[part 2 of 2: packages /ComponentType/IvtrIDcLimn/IvtrIDcLimnMAIN to /VehicleProject]
AUTOSAR XML (schema 4.0)
package /ComponentType/IvtrIDcLimn/IvtrIDcLimnMAIN
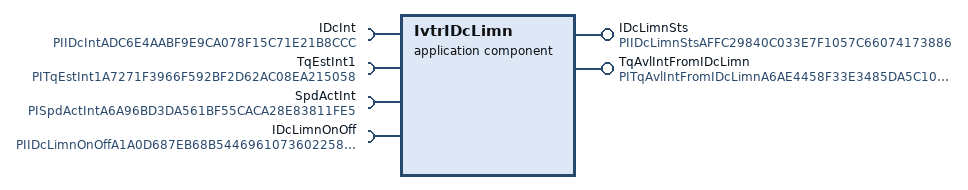
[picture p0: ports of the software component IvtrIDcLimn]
  application sw component type IvtrIDcLimn
    require port IDcInt: nonqueued-receiver-com-spec{data-element=IDcInt, init-value=constant-reference=A566A6590FA167C633F64C4171ADCCB7}, required-interface=PIIDcIntADC6E4AABF9E9CA078F15C71E21B8CCC
    require port TqEstInt1: nonqueued-receiver-com-spec{data-element=TqEstInt1, init-value=constant-reference=A566A6590FA167C633F64C4171ADCCB7}, required-interface=PITqEstInt1A7271F3966F592BF2D62AC08EA215058
    provide port IDcLimnSts: nonqueued-sender-com-spec{data-element=IDcLimnSts, init-value=constant-reference=A2AB2663EDCB674997EFCB4941EAE573}, provided-interface=PIIDcLimnStsAFFC29840C033E7F1057C66074173886
    provide port TqAvlIntFromIDcLimn: nonqueued-sender-com-spec{data-element=TqAvlIntFromIDcLimn, init-value=constant-reference=A6571BE8D08FA8624FE034351C65BBB8}, provided-interface=PITqAvlIntFromIDcLimnA6AE4458F33E3485DA5C10021B0ED5EF
    require port SpdActInt: nonqueued-receiver-com-spec{data-element=SpdActInt, init-value=constant-reference=A566A6590FA167C633F64C4171ADCCB7}, required-interface=PISpdActIntA6A96BD3DA561BF55CACA28E83811FE5
    require port IDcLimnOnOff: nonqueued-receiver-com-spec{data-element=IDcLimnOnOff, init-value=constant-reference=A2AB2663EDCB674997EFCB4941EAE573}, required-interface=PIIDcLimnOnOffA1A0D687EB68B5446961073602258F9F
    behavior BE35d78db7de42c8a51d7b3d700dddb2: handle-termination-and-restart=NO-SUPPORT
      port-api-options:
        enable-take-address=false, indirect-api=false, port=IvtrIDcLimn/IDcInt
        enable-take-address=false, indirect-api=false, port=IvtrIDcLimn/TqEstInt1
        enable-take-address=false, indirect-api=false, port=IDcLimnSts
        enable-take-address=false, indirect-api=false, port=TqAvlIntFromIDcLimn
        enable-take-address=false, indirect-api=false, port=IvtrIDcLimn/SpdActInt
        enable-take-address=false, indirect-api=false, port=IDcLimnOnOff
package /ComponentType/IsgImmo/IsgImmoMAIN
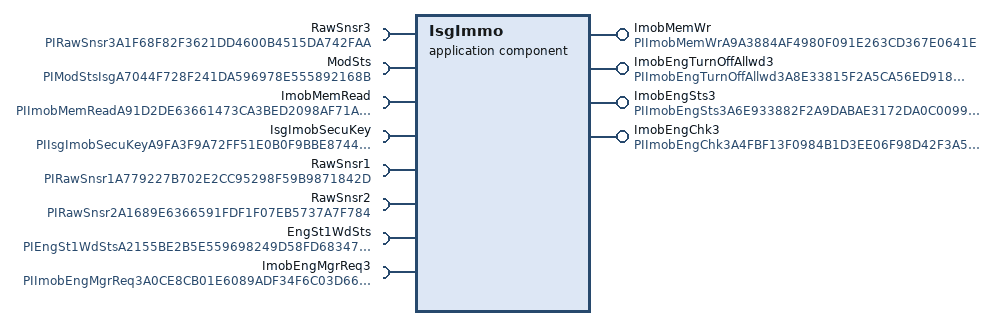
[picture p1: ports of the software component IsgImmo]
  application sw component type IsgImmo
    provide port ImobMemWr: nonqueued-sender-com-spec{data-element=ImobMemWr, init-value=constant-reference=A2AB2663EDCB674997EFCB4941EAE573}, provided-interface=PIImobMemWrA9A3884AF4980F091E263CD367E0641E
    provide port ImobEngTurnOffAllwd3: nonqueued-sender-com-spec{data-element=ImobEngTurnOffAllwd3, init-value=constant-reference=A2AB2663EDCB674997EFCB4941EAE573}, provided-interface=PIImobEngTurnOffAllwd3A8E33815F2A5CA56ED918D0B41C26BA7
    4 x require port:
      RawSnsr3: nonqueued-receiver-com-spec{data-element=RawSnsr3, init-value=constant-reference=A566A6590FA167C633F64C4171ADCCB7}, required-interface=PIRawSnsr3A1F68F82F3621DD4600B4515DA742FAA
      ModSts: nonqueued-receiver-com-spec{data-element=ModStsIsg, init-value=constant-reference=A2AB2663EDCB674997EFCB4941EAE573}, required-interface=PIModStsIsgA7044F728F241DA596978E555892168B
      ImobMemRead: nonqueued-receiver-com-spec{data-element=ImobMemRead, init-value=constant-reference=A2AB2663EDCB674997EFCB4941EAE573}, required-interface=PIImobMemReadA91D2DE63661473CA3BED2098AF71AA2
      IsgImobSecuKey: nonqueued-receiver-com-spec{data-element=IsgImobSecuKey, init-value=constant-reference=AA9EE529BC7CE8EA3A0A158775B5EB0F}, required-interface=PIIsgImobSecuKeyA9FA3F9A72FF51E0B0F9BBE874419BC9
    provide port ImobEngSts3: nonqueued-sender-com-spec{data-element=ImobEngSts3, init-value=constant-reference=A2AB2663EDCB674997EFCB4941EAE573}, provided-interface=PIImobEngSts3A6E933882F2A9DABAE3172DA0C0099F9
    require port RawSnsr1: nonqueued-receiver-com-spec{data-element=RawSnsr1, init-value=constant-reference=A566A6590FA167C633F64C4171ADCCB7}, required-interface=PIRawSnsr1A779227B702E2CC95298F59B9871842D
    require port RawSnsr2: nonqueued-receiver-com-spec{data-element=RawSnsr2, init-value=constant-reference=A566A6590FA167C633F64C4171ADCCB7}, required-interface=PIRawSnsr2A1689E6366591FDF1F07EB5737A7F784
    provide port ImobEngChk3: nonqueued-sender-com-spec{data-element=ImobEngChk3, init-value=constant-reference=A978A77034898F3865BDF257EAEB987B}, provided-interface=PIImobEngChk3A4FBF13F0984B1D3EE06F98D42F3A586
    require port EngSt1WdSts: nonqueued-receiver-com-spec{data-element=EngSt1WdSts, init-value=constant-reference=A636F88E591B4F4A2849AD5E95838F02}, required-interface=PIEngSt1WdStsA2155BE2B5E559698249D58FD6834766
    require port ImobEngMgrReq3: nonqueued-receiver-com-spec{data-element=ImobEngMgrReq3, init-value=constant-reference=A2DE60DBB38156AAEB7CD85B81802804}, required-interface=PIImobEngMgrReq3A0CE8CB01E6089ADF34F6C03D6663521
    behavior BE7ec634f2af4344bb8b143e4ec89d72: handle-termination-and-restart=NO-SUPPORT
      port-api-options:
        enable-take-address=false, indirect-api=false, port=IsgImmo/ImobMemWr
        enable-take-address=false, indirect-api=false, port=ImobEngTurnOffAllwd3
        enable-take-address=false, indirect-api=false, port=IsgImmo/RawSnsr3
        enable-take-address=false, indirect-api=false, port=ModSts
        enable-take-address=false, indirect-api=false, port=IsgImmo/ImobMemRead
        enable-take-address=false, indirect-api=false, port=IsgImmo/IsgImobSecuKey
        enable-take-address=false, indirect-api=false, port=IsgImmo/ImobEngSts3
        enable-take-address=false, indirect-api=false, port=IsgImmo/RawSnsr1
        enable-take-address=false, indirect-api=false, port=IsgImmo/RawSnsr2
        enable-take-address=false, indirect-api=false, port=IsgImmo/ImobEngChk3
        enable-take-address=false, indirect-api=false, port=IsgImmo/EngSt1WdSts
        enable-take-address=false, indirect-api=false, port=IsgImmo/ImobEngMgrReq3
package /ComponentType/CMACIDDIfCptOut/CMACIDDIfCptOutMAIN
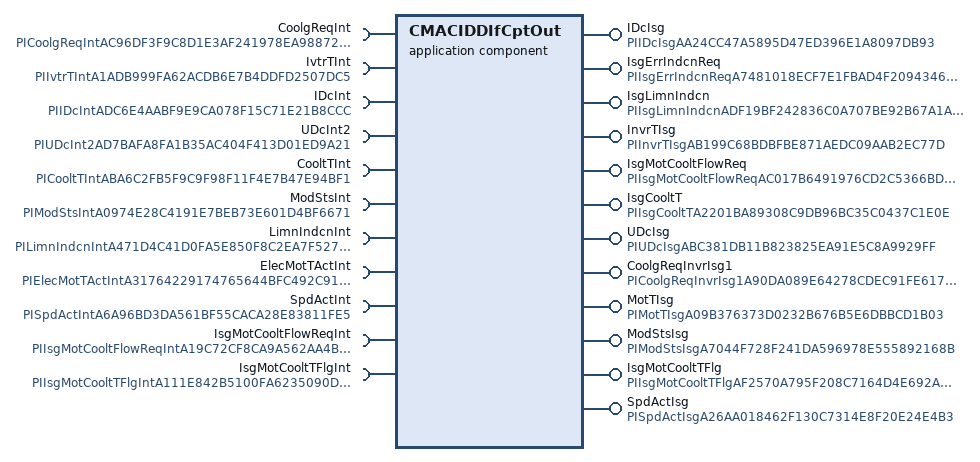
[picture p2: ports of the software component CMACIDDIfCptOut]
  application sw component type CMACIDDIfCptOut
    7 x require port:
      CoolgReqInt: nonqueued-receiver-com-spec{data-element=CoolgReqInt, init-value=constant-reference=A2AB2663EDCB674997EFCB4941EAE573}, required-interface=PICoolgReqIntAC96DF3F9C8D1E3AF241978EA9887249
      IvtrTInt: nonqueued-receiver-com-spec{data-element=IvtrTInt, init-value=constant-reference=A566A6590FA167C633F64C4171ADCCB7}, required-interface=PIIvtrTIntA1ADB999FA62ACDB6E7B4DDFD2507DC5
      IDcInt: nonqueued-receiver-com-spec{data-element=IDcInt, init-value=constant-reference=A566A6590FA167C633F64C4171ADCCB7}, required-interface=PIIDcIntADC6E4AABF9E9CA078F15C71E21B8CCC
      UDcInt2: nonqueued-receiver-com-spec{data-element=UDcInt2, init-value=constant-reference=A566A6590FA167C633F64C4171ADCCB7}, required-interface=PIUDcInt2AD7BAFA8FA1B35AC404F413D01ED9A21
      CooltTInt: nonqueued-receiver-com-spec{data-element=CooltTInt, init-value=constant-reference=A566A6590FA167C633F64C4171ADCCB7}, required-interface=PICooltTIntABA6C2FB5F9C9F98F11F4E7B47E94BF1
      ModStsInt: nonqueued-receiver-com-spec{data-element=ModStsInt, init-value=constant-reference=A2AB2663EDCB674997EFCB4941EAE573}, required-interface=PIModStsIntA0974E28C4191E7BEB73E601D4BF6671
      LimnIndcnInt: nonqueued-receiver-com-spec{data-element=LimnIndcnInt, init-value=constant-reference=A2AB2663EDCB674997EFCB4941EAE573}, required-interface=PILimnIndcnIntA471D4C41D0FA5E850F8C2EA7F52740F
    provide port IDcIsg: nonqueued-sender-com-spec{data-element=IDcIsg, init-value=constant-reference=A566A6590FA167C633F64C4171ADCCB7}, provided-interface=PIIDcIsgAA24CC47A5895D47ED396E1A8097DB93
    provide port IsgErrIndcnReq: nonqueued-sender-com-spec{data-element=IsgErrIndcnReq, init-value=constant-reference=A2AB2663EDCB674997EFCB4941EAE573}, provided-interface=PIIsgErrIndcnReqA7481018ECF7E1FBAD4F2094346D0B08
    require port ElecMotTActInt: nonqueued-receiver-com-spec{data-element=ElecMotTActInt, init-value=constant-reference=A566A6590FA167C633F64C4171ADCCB7}, required-interface=PIElecMotTActIntA31764229174765644BFC492C91799B4
    6 x provide port:
      IsgLimnIndcn: nonqueued-sender-com-spec{data-element=IsgLimnIndcn, init-value=constant-reference=A2AB2663EDCB674997EFCB4941EAE573}, provided-interface=PIIsgLimnIndcnADF19BF242836C0A707BE92B67A1A3C9
      InvrTIsg: nonqueued-sender-com-spec{data-element=InvrTIsg, init-value=constant-reference=A566A6590FA167C633F64C4171ADCCB7}, provided-interface=PIInvrTIsgAB199C68BDBFBE871AEDC09AAB2EC77D
      IsgMotCooltFlowReq: nonqueued-sender-com-spec{data-element=IsgMotCooltFlowReq, init-value=constant-reference=A566A6590FA167C633F64C4171ADCCB7}, provided-interface=PIIsgMotCooltFlowReqAC017B6491976CD2C5366BD7CAC36C21
      IsgCooltT: nonqueued-sender-com-spec{data-element=IsgCooltT, init-value=constant-reference=A566A6590FA167C633F64C4171ADCCB7}, provided-interface=PIIsgCooltTA2201BA89308C9DB96BC35C0437C1E0E
      UDcIsg: nonqueued-sender-com-spec{data-element=UDcIsg, init-value=constant-reference=A566A6590FA167C633F64C4171ADCCB7}, provided-interface=PIUDcIsgABC381DB11B823825EA91E5C8A9929FF
      CoolgReqInvrIsg1: nonqueued-sender-com-spec{data-element=CoolgReqInvrIsg1, init-value=constant-reference=A2AB2663EDCB674997EFCB4941EAE573}, provided-interface=PICoolgReqInvrIsg1A90DA089E64278CDEC91FE617833644E
    require port SpdActInt: nonqueued-receiver-com-spec{data-element=SpdActInt, init-value=constant-reference=A566A6590FA167C633F64C4171ADCCB7}, required-interface=PISpdActIntA6A96BD3DA561BF55CACA28E83811FE5
    provide port MotTIsg: nonqueued-sender-com-spec{data-element=MotTIsg, init-value=constant-reference=A566A6590FA167C633F64C4171ADCCB7}, provided-interface=PIMotTIsgA09B376373D0232B676B5E6DBBCD1B03
    require port IsgMotCooltFlowReqInt: nonqueued-receiver-com-spec{data-element=IsgMotCooltFlowReqInt, init-value=constant-reference=A566A6590FA167C633F64C4171ADCCB7}, required-interface=PIIsgMotCooltFlowReqIntA19C72CF8CA9A562AA4BC89712FF8931
    provide port ModStsIsg: nonqueued-sender-com-spec{data-element=ModStsIsg, init-value=constant-reference=A2AB2663EDCB674997EFCB4941EAE573}, provided-interface=PIModStsIsgA7044F728F241DA596978E555892168B
    provide port IsgMotCooltTFlg: nonqueued-sender-com-spec{data-element=IsgMotCooltTFlg, init-value=constant-reference=A2AB2663EDCB674997EFCB4941EAE573}, provided-interface=PIIsgMotCooltTFlgAF2570A795F208C7164D4E692AD44EF5
    require port IsgMotCooltTFlgInt: nonqueued-receiver-com-spec{data-element=IsgMotCooltTFlgInt, init-value=constant-reference=AD30053758475D867C29EE0F5723584A}, required-interface=PIIsgMotCooltTFlgIntA111E842B5100FA6235090DA6780D515
    provide port SpdActIsg: nonqueued-sender-com-spec{data-element=SpdActIsg, init-value=constant-reference=A2AB2663EDCB674997EFCB4941EAE573}, provided-interface=PISpdActIsgA26AA018462F130C7314E8F20E24E4B3
    behavior BEff149eeec84c2b8b5259282cef4e47: handle-termination-and-restart=NO-SUPPORT
      port-api-options:
        enable-take-address=false, indirect-api=false, port=CoolgReqInt
        enable-take-address=false, indirect-api=false, port=CMACIDDIfCptOut/IvtrTInt
        enable-take-address=false, indirect-api=false, port=CMACIDDIfCptOut/IDcInt
        enable-take-address=false, indirect-api=false, port=CMACIDDIfCptOut/UDcInt2
        enable-take-address=false, indirect-api=false, port=CMACIDDIfCptOut/CooltTInt
        enable-take-address=false, indirect-api=false, port=ModStsInt
        enable-take-address=false, indirect-api=false, port=LimnIndcnInt
        enable-take-address=false, indirect-api=false, port=CMACIDDIfCptOut/IDcIsg
        enable-take-address=false, indirect-api=false, port=CMACIDDIfCptOut/IsgErrIndcnReq
        enable-take-address=false, indirect-api=false, port=CMACIDDIfCptOut/ElecMotTActInt
        enable-take-address=false, indirect-api=false, port=CMACIDDIfCptOut/IsgLimnIndcn
        enable-take-address=false, indirect-api=false, port=CMACIDDIfCptOut/InvrTIsg
        enable-take-address=false, indirect-api=false, port=CMACIDDIfCptOut/IsgMotCooltFlowReq
        enable-take-address=false, indirect-api=false, port=CMACIDDIfCptOut/IsgCooltT
        enable-take-address=false, indirect-api=false, port=CMACIDDIfCptOut/UDcIsg
        enable-take-address=false, indirect-api=false, port=CMACIDDIfCptOut/CoolgReqInvrIsg1
        enable-take-address=false, indirect-api=false, port=CMACIDDIfCptOut/SpdActInt
        enable-take-address=false, indirect-api=false, port=CMACIDDIfCptOut/MotTIsg
        enable-take-address=false, indirect-api=false, port=IsgMotCooltFlowReqInt
        enable-take-address=false, indirect-api=false, port=CMACIDDIfCptOut/ModStsIsg
        enable-take-address=false, indirect-api=false, port=CMACIDDIfCptOut/IsgMotCooltTFlg
        enable-take-address=false, indirect-api=false, port=IsgMotCooltTFlgInt
        enable-take-address=false, indirect-api=false, port=CMACIDDIfCptOut/SpdActIsg
package /ComponentType/IvtrAntiSpin/IvtrAntiSpinMAIN
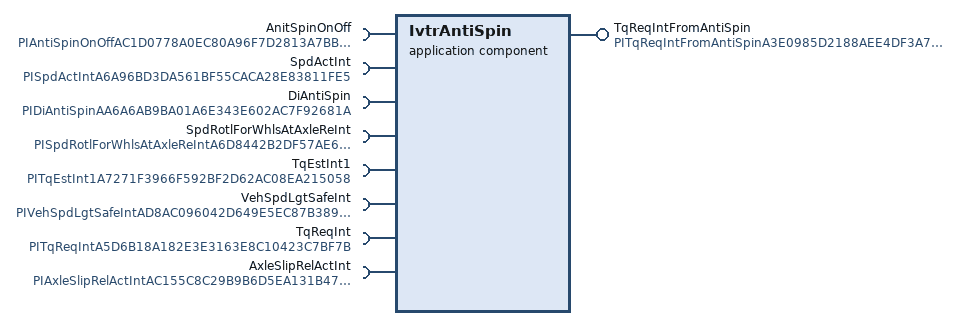
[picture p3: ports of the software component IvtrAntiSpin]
  application sw component type IvtrAntiSpin
    require port AnitSpinOnOff: nonqueued-receiver-com-spec{data-element=AntiSpinOnOff, init-value=constant-reference=AD30053758475D867C29EE0F5723584A}, required-interface=PIAntiSpinOnOffAC1D0778A0EC80A96F7D2813A7BB259C
    require port SpdActInt: nonqueued-receiver-com-spec{data-element=SpdActInt, init-value=constant-reference=A566A6590FA167C633F64C4171ADCCB7}, required-interface=PISpdActIntA6A96BD3DA561BF55CACA28E83811FE5
    provide port TqReqIntFromAntiSpin: nonqueued-sender-com-spec{data-element=TqReqIntFromAntiSpin, init-value=constant-reference=A566A6590FA167C633F64C4171ADCCB7}, provided-interface=PITqReqIntFromAntiSpinA3E0985D2188AEE4DF3A78C4373D692A
    6 x require port:
      DiAntiSpin: nonqueued-receiver-com-spec{data-element=DiAntiSpin, init-value=constant-reference=AD30053758475D867C29EE0F5723584A}, required-interface=PIDiAntiSpinAA6A6AB9BA01A6E343E602AC7F92681A
      SpdRotlForWhlsAtAxleReInt: nonqueued-receiver-com-spec{data-element=SpdRotlForWhlsAtAxleReInt, init-value=constant-reference=A566A6590FA167C633F64C4171ADCCB7}, required-interface=PISpdRotlForWhlsAtAxleReIntA6D8442B2DF57AE61F7FA90FE332F100
      TqEstInt1: nonqueued-receiver-com-spec{data-element=TqEstInt1, init-value=constant-reference=A566A6590FA167C633F64C4171ADCCB7}, required-interface=PITqEstInt1A7271F3966F592BF2D62AC08EA215058
      VehSpdLgtSafeInt: nonqueued-receiver-com-spec{data-element=VehSpdLgtSafeInt, init-value=constant-reference=A68FE985916865C70A611D0FFC6B9CF2}, required-interface=PIVehSpdLgtSafeIntAD8AC096042D649E5EC87B3898F1B812
      TqReqInt: nonqueued-receiver-com-spec{data-element=TqReqInt, init-value=constant-reference=A566A6590FA167C633F64C4171ADCCB7}, required-interface=PITqReqIntA5D6B18A182E3E3163E8C10423C7BF7B
      AxleSlipRelActInt: nonqueued-receiver-com-spec{data-element=AxleSlipRelActInt, init-value=constant-reference=A566A6590FA167C633F64C4171ADCCB7}, required-interface=PIAxleSlipRelActIntAC155C8C29B9B6D5EA131B477AEAA643
    behavior BEb162d0eb2e4f02bc2c140d4cab38fc: handle-termination-and-restart=NO-SUPPORT
      port-api-options:
        enable-take-address=false, indirect-api=false, port=AnitSpinOnOff
        enable-take-address=false, indirect-api=false, port=IvtrAntiSpin/SpdActInt
        enable-take-address=false, indirect-api=false, port=TqReqIntFromAntiSpin
        enable-take-address=false, indirect-api=false, port=DiAntiSpin
        enable-take-address=false, indirect-api=false, port=IvtrAntiSpin/SpdRotlForWhlsAtAxleReInt
        enable-take-address=false, indirect-api=false, port=IvtrAntiSpin/TqEstInt1
        enable-take-address=false, indirect-api=false, port=VehSpdLgtSafeInt
        enable-take-address=false, indirect-api=false, port=IvtrAntiSpin/TqReqInt
        enable-take-address=false, indirect-api=false, port=AxleSlipRelActInt
package /ComponentType/IvtrElecMotTLimn/IvtrElecMotTLimnMAIN
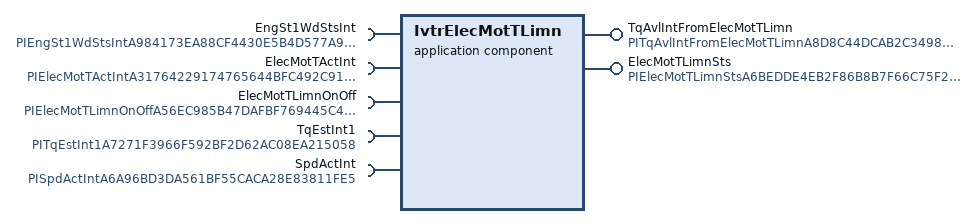
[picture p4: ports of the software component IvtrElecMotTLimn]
  application sw component type IvtrElecMotTLimn
    require port EngSt1WdStsInt: nonqueued-receiver-com-spec{data-element=EngSt1WdStsInt, init-value=constant-reference=A636F88E591B4F4A2849AD5E95838F02}, required-interface=PIEngSt1WdStsIntA984173EA88CF4430E5B4D577A9BEE8A
    require port ElecMotTActInt: nonqueued-receiver-com-spec{data-element=ElecMotTActInt, init-value=constant-reference=A566A6590FA167C633F64C4171ADCCB7}, required-interface=PIElecMotTActIntA31764229174765644BFC492C91799B4
    provide port TqAvlIntFromElecMotTLimn: nonqueued-sender-com-spec{data-element=TqAvlIntFromElecMotTLimn, init-value=constant-reference=A6571BE8D08FA8624FE034351C65BBB8}, provided-interface=PITqAvlIntFromElecMotTLimnA8D8C44DCAB2C3498F4B4354A447D7C6
    require port ElecMotTLimnOnOff: nonqueued-receiver-com-spec{data-element=ElecMotTLimnOnOff, init-value=constant-reference=A2AB2663EDCB674997EFCB4941EAE573}, required-interface=PIElecMotTLimnOnOffA56EC985B47DAFBF769445C481FDAB70
    require port TqEstInt1: nonqueued-receiver-com-spec{data-element=TqEstInt1, init-value=constant-reference=A566A6590FA167C633F64C4171ADCCB7}, required-interface=PITqEstInt1A7271F3966F592BF2D62AC08EA215058
    provide port ElecMotTLimnSts: nonqueued-sender-com-spec{data-element=ElecMotTLimnSts, init-value=constant-reference=A2AB2663EDCB674997EFCB4941EAE573}, provided-interface=PIElecMotTLimnStsA6BEDDE4EB2F86B8B7F66C75F285B97F
    require port SpdActInt: nonqueued-receiver-com-spec{data-element=SpdActInt, init-value=constant-reference=A566A6590FA167C633F64C4171ADCCB7}, required-interface=PISpdActIntA6A96BD3DA561BF55CACA28E83811FE5
    behavior BE808a822f444aabb96fe5b11ea65a39: handle-termination-and-restart=NO-SUPPORT
      port-api-options:
        enable-take-address=false, indirect-api=false, port=IvtrElecMotTLimn/EngSt1WdStsInt
        enable-take-address=false, indirect-api=false, port=IvtrElecMotTLimn/ElecMotTActInt
        enable-take-address=false, indirect-api=false, port=TqAvlIntFromElecMotTLimn
        enable-take-address=false, indirect-api=false, port=ElecMotTLimnOnOff
        enable-take-address=false, indirect-api=false, port=IvtrElecMotTLimn/TqEstInt1
        enable-take-address=false, indirect-api=false, port=ElecMotTLimnSts
        enable-take-address=false, indirect-api=false, port=IvtrElecMotTLimn/SpdActInt
package /ComponentType/IvtrUDcLimn/IvtrUDcLimnMAIN
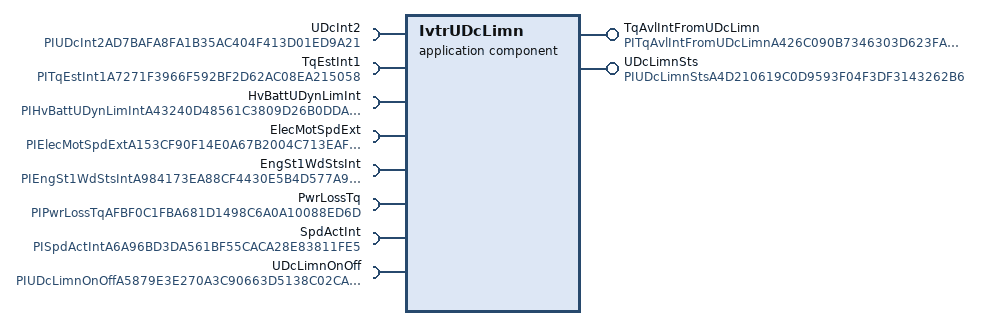
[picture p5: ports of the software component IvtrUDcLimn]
  application sw component type IvtrUDcLimn
    provide port TqAvlIntFromUDcLimn: nonqueued-sender-com-spec{data-element=TqAvlIntFromUDcLimn, init-value=constant-reference=A8CFFE3621C1DA13E6FF691AE3A9D3C1}, provided-interface=PITqAvlIntFromUDcLimnA426C090B7346303D623FAFF22E09D3B
    7 x require port:
      UDcInt2: nonqueued-receiver-com-spec{data-element=UDcInt2, init-value=constant-reference=A566A6590FA167C633F64C4171ADCCB7}, required-interface=PIUDcInt2AD7BAFA8FA1B35AC404F413D01ED9A21
      TqEstInt1: nonqueued-receiver-com-spec{data-element=TqEstInt1, init-value=constant-reference=A566A6590FA167C633F64C4171ADCCB7}, required-interface=PITqEstInt1A7271F3966F592BF2D62AC08EA215058
      HvBattUDynLimInt: nonqueued-receiver-com-spec{data-element=HvBattUDynLimInt, init-value=constant-reference=A475F4F393542C3A8168E5F3043367CB}, required-interface=PIHvBattUDynLimIntA43240D48561C3809D26B0DDADA0994C
      ElecMotSpdExt: nonqueued-receiver-com-spec{data-element=ElecMotSpdExt, init-value=constant-reference=A566A6590FA167C633F64C4171ADCCB7}, required-interface=PIElecMotSpdExtA153CF90F14E0A67B2004C713EAF537C
      EngSt1WdStsInt: nonqueued-receiver-com-spec{data-element=EngSt1WdStsInt, init-value=constant-reference=A636F88E591B4F4A2849AD5E95838F02}, required-interface=PIEngSt1WdStsIntA984173EA88CF4430E5B4D577A9BEE8A
      PwrLossTq: nonqueued-receiver-com-spec{data-element=PwrLossTq, init-value=constant-reference=A566A6590FA167C633F64C4171ADCCB7}, required-interface=PIPwrLossTqAFBF0C1FBA681D1498C6A0A10088ED6D
      SpdActInt: nonqueued-receiver-com-spec{data-element=SpdActInt, init-value=constant-reference=A566A6590FA167C633F64C4171ADCCB7}, required-interface=PISpdActIntA6A96BD3DA561BF55CACA28E83811FE5
    provide port UDcLimnSts: nonqueued-sender-com-spec{data-element=UDcLimnSts, init-value=constant-reference=A2AB2663EDCB674997EFCB4941EAE573}, provided-interface=PIUDcLimnStsA4D210619C0D9593F04F3DF3143262B6
    require port UDcLimnOnOff: nonqueued-receiver-com-spec{data-element=UDcLimnOnOff, init-value=constant-reference=A2AB2663EDCB674997EFCB4941EAE573}, required-interface=PIUDcLimnOnOffA5879E3E270A3C90663D5138C02CA256
    behavior BE011aebbdd8486cb71f85ab897cc588: handle-termination-and-restart=NO-SUPPORT
      port-api-options:
        enable-take-address=false, indirect-api=false, port=TqAvlIntFromUDcLimn
        enable-take-address=false, indirect-api=false, port=IvtrUDcLimn/UDcInt2
        enable-take-address=false, indirect-api=false, port=IvtrUDcLimn/TqEstInt1
        enable-take-address=false, indirect-api=false, port=HvBattUDynLimInt
        enable-take-address=false, indirect-api=false, port=IvtrUDcLimn/ElecMotSpdExt
        enable-take-address=false, indirect-api=false, port=IvtrUDcLimn/EngSt1WdStsInt
        enable-take-address=false, indirect-api=false, port=PwrLossTq
        enable-take-address=false, indirect-api=false, port=IvtrUDcLimn/SpdActInt
        enable-take-address=false, indirect-api=false, port=UDcLimnSts
        enable-take-address=false, indirect-api=false, port=UDcLimnOnOff
package /ComponentType/IvtrSpdSetCtrl/IvtrSpdSetCtrlMAIN
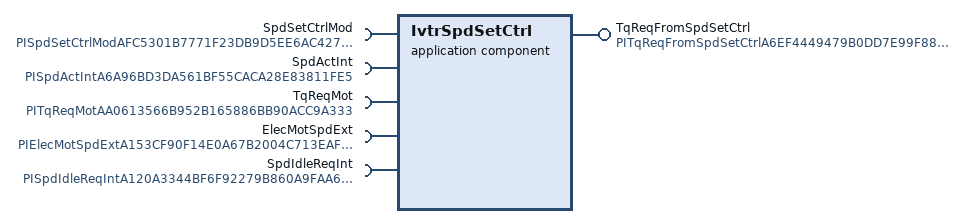
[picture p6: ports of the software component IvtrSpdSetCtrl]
  application sw component type IvtrSpdSetCtrl
    require port SpdSetCtrlMod: nonqueued-receiver-com-spec{data-element=SpdSetCtrlMod, init-value=constant-reference=A2AB2663EDCB674997EFCB4941EAE573}, required-interface=PISpdSetCtrlModAFC5301B7771F23DB9D5EE6AC427D0DF
    provide port TqReqFromSpdSetCtrl: nonqueued-sender-com-spec{data-element=TqReqFromSpdSetCtrl, init-value=constant-reference=A566A6590FA167C633F64C4171ADCCB7}, provided-interface=PITqReqFromSpdSetCtrlA6EF4449479B0DD7E99F884852E50B53
    4 x require port:
      SpdActInt: nonqueued-receiver-com-spec{data-element=SpdActInt, init-value=constant-reference=A566A6590FA167C633F64C4171ADCCB7}, required-interface=PISpdActIntA6A96BD3DA561BF55CACA28E83811FE5
      TqReqMot: nonqueued-receiver-com-spec{data-element=TqReqMot, init-value=constant-reference=A566A6590FA167C633F64C4171ADCCB7}, required-interface=PITqReqMotAA0613566B952B165886BB90ACC9A333
      ElecMotSpdExt: nonqueued-receiver-com-spec{data-element=ElecMotSpdExt, init-value=constant-reference=A566A6590FA167C633F64C4171ADCCB7}, required-interface=PIElecMotSpdExtA153CF90F14E0A67B2004C713EAF537C
      SpdIdleReqInt: nonqueued-receiver-com-spec{data-element=SpdIdleReqInt, init-value=constant-reference=A566A6590FA167C633F64C4171ADCCB7}, required-interface=PISpdIdleReqIntA120A3344BF6F92279B860A9FAA6ECAE
    behavior BEadc5c64acc4f2e90d294c4262b7282: handle-termination-and-restart=NO-SUPPORT
      port-api-options:
        enable-take-address=false, indirect-api=false, port=SpdSetCtrlMod
        enable-take-address=false, indirect-api=false, port=TqReqFromSpdSetCtrl
        enable-take-address=false, indirect-api=false, port=IvtrSpdSetCtrl/SpdActInt
        enable-take-address=false, indirect-api=false, port=IvtrSpdSetCtrl/TqReqMot
        enable-take-address=false, indirect-api=false, port=IvtrSpdSetCtrl/ElecMotSpdExt
        enable-take-address=false, indirect-api=false, port=SpdIdleReqInt
package /ComponentType/IvtrErrIndcn/IvtrErrIndcnMAIN
  application sw component type IvtrErrIndcn
    behavior BE44068fd61445ff8b9ba4e3c95e7bb1: handle-termination-and-restart=NO-SUPPORT
package /ComponentType/IvtrElecMotTqAvlCalcn/IvtrElecMotTqAvlCalcnMAIN
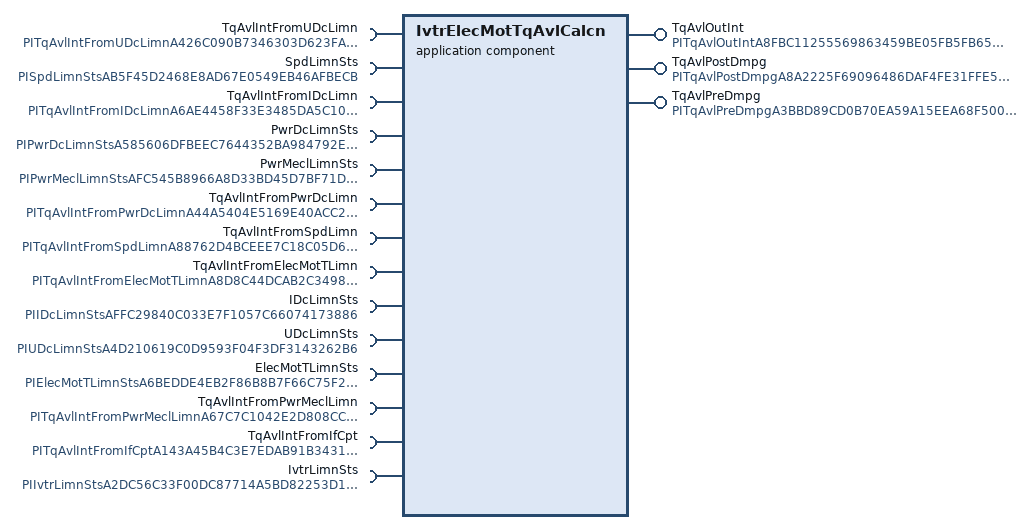
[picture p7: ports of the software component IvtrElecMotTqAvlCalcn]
  application sw component type IvtrElecMotTqAvlCalcn
    require port TqAvlIntFromUDcLimn: nonqueued-receiver-com-spec{data-element=TqAvlIntFromUDcLimn, init-value=constant-reference=A8CFFE3621C1DA13E6FF691AE3A9D3C1}, required-interface=PITqAvlIntFromUDcLimnA426C090B7346303D623FAFF22E09D3B
    require port SpdLimnSts: nonqueued-receiver-com-spec{data-element=SpdLimnSts, init-value=constant-reference=A2AB2663EDCB674997EFCB4941EAE573}, required-interface=PISpdLimnStsAB5F45D2468E8AD67E0549EB46AFBECB
    provide port TqAvlOutInt: nonqueued-sender-com-spec{data-element=TqAvlOutInt, init-value=constant-reference=A8CFFE3621C1DA13E6FF691AE3A9D3C1}, provided-interface=PITqAvlOutIntA8FBC11255569863459BE05FB5FB6599
    6 x require port:
      TqAvlIntFromIDcLimn: nonqueued-receiver-com-spec{data-element=TqAvlIntFromIDcLimn, init-value=constant-reference=A8CFFE3621C1DA13E6FF691AE3A9D3C1}, required-interface=PITqAvlIntFromIDcLimnA6AE4458F33E3485DA5C10021B0ED5EF
      PwrDcLimnSts: nonqueued-receiver-com-spec{data-element=PwrDcLimnSts, init-value=constant-reference=A2AB2663EDCB674997EFCB4941EAE573}, required-interface=PIPwrDcLimnStsA585606DFBEEC7644352BA984792E3DF
      PwrMeclLimnSts: nonqueued-receiver-com-spec{data-element=PwrMeclLimnSts, init-value=constant-reference=A2AB2663EDCB674997EFCB4941EAE573}, required-interface=PIPwrMeclLimnStsAFC545B8966A8D33BD45D7BF71D6D720
      TqAvlIntFromPwrDcLimn: nonqueued-receiver-com-spec{data-element=TqAvlIntFromPwrDcLimn, init-value=constant-reference=A8CFFE3621C1DA13E6FF691AE3A9D3C1}, required-interface=PITqAvlIntFromPwrDcLimnA44A5404E5169E40ACC2FA97F3F218EE
      TqAvlIntFromSpdLimn: nonqueued-receiver-com-spec{data-element=TqAvlIntFromSpdLimn, init-value=constant-reference=A8CFFE3621C1DA13E6FF691AE3A9D3C1}, required-interface=PITqAvlIntFromSpdLimnA88762D4BCEEE7C18C05D620D2A53FB7
      TqAvlIntFromElecMotTLimn: nonqueued-receiver-com-spec{data-element=TqAvlIntFromElecMotTLimn, init-value=constant-reference=A8CFFE3621C1DA13E6FF691AE3A9D3C1}, required-interface=PITqAvlIntFromElecMotTLimnA8D8C44DCAB2C3498F4B4354A447D7C6
    provide port TqAvlPostDmpg: nonqueued-sender-com-spec{data-element=TqAvlPostDmpg, init-value=constant-reference=A8CFFE3621C1DA13E6FF691AE3A9D3C1}, provided-interface=PITqAvlPostDmpgA8A2225F69096486DAF4FE31FFE52A89
    provide port TqAvlPreDmpg: nonqueued-sender-com-spec{data-element=TqAvlPreDmpg, init-value=constant-reference=A8CFFE3621C1DA13E6FF691AE3A9D3C1}, provided-interface=PITqAvlPreDmpgA3BBD89CD0B70EA59A15EEA68F5001F0
    6 x require port:
      IDcLimnSts: nonqueued-receiver-com-spec{data-element=IDcLimnSts, init-value=constant-reference=A2AB2663EDCB674997EFCB4941EAE573}, required-interface=PIIDcLimnStsAFFC29840C033E7F1057C66074173886
      UDcLimnSts: nonqueued-receiver-com-spec{data-element=UDcLimnSts, init-value=constant-reference=A2AB2663EDCB674997EFCB4941EAE573}, required-interface=PIUDcLimnStsA4D210619C0D9593F04F3DF3143262B6
      ElecMotTLimnSts: nonqueued-receiver-com-spec{data-element=ElecMotTLimnSts, init-value=constant-reference=A2AB2663EDCB674997EFCB4941EAE573}, required-interface=PIElecMotTLimnStsA6BEDDE4EB2F86B8B7F66C75F285B97F
      TqAvlIntFromPwrMeclLimn: nonqueued-receiver-com-spec{data-element=TqAvlIntFromPwrMeclLimn, init-value=constant-reference=A8CFFE3621C1DA13E6FF691AE3A9D3C1}, required-interface=PITqAvlIntFromPwrMeclLimnA67C7C1042E2D808CCF62C1CA5324947
      TqAvlIntFromIfCpt: nonqueued-receiver-com-spec{data-element=TqAvlIntFromIfCpt, init-value=constant-reference=A8CFFE3621C1DA13E6FF691AE3A9D3C1}, required-interface=PITqAvlIntFromIfCptA143A45B4C3E7EDAB91B3431BED4F1CC
      IvtrLimnSts: nonqueued-receiver-com-spec{data-element=IvtrLimnSts, init-value=constant-reference=A2AB2663EDCB674997EFCB4941EAE573}, required-interface=PIIvtrLimnStsA2DC56C33F00DC87714A5BD82253D1CF
    behavior BE1711f352eb428c9b588567ed74cb7b: handle-termination-and-restart=NO-SUPPORT
      port-api-options:
        enable-take-address=false, indirect-api=false, port=TqAvlIntFromUDcLimn
        enable-take-address=false, indirect-api=false, port=SpdLimnSts
        enable-take-address=false, indirect-api=false, port=IvtrElecMotTqAvlCalcn/TqAvlOutInt
        enable-take-address=false, indirect-api=false, port=TqAvlIntFromIDcLimn
        enable-take-address=false, indirect-api=false, port=PwrDcLimnSts
        enable-take-address=false, indirect-api=false, port=PwrMeclLimnSts
        enable-take-address=false, indirect-api=false, port=TqAvlIntFromPwrDcLimn
        enable-take-address=false, indirect-api=false, port=TqAvlIntFromSpdLimn
        enable-take-address=false, indirect-api=false, port=TqAvlIntFromElecMotTLimn
        enable-take-address=false, indirect-api=false, port=TqAvlPostDmpg
        enable-take-address=false, indirect-api=false, port=TqAvlPreDmpg
        enable-take-address=false, indirect-api=false, port=IDcLimnSts
        enable-take-address=false, indirect-api=false, port=UDcLimnSts
        enable-take-address=false, indirect-api=false, port=ElecMotTLimnSts
        enable-take-address=false, indirect-api=false, port=TqAvlIntFromPwrMeclLimn
        enable-take-address=false, indirect-api=false, port=IvtrElecMotTqAvlCalcn/TqAvlIntFromIfCpt
        enable-take-address=false, indirect-api=false, port=IvtrElecMotTqAvlCalcn/IvtrLimnSts
package /ComponentType/IgmVccAppl/IgmVccApplMAIN
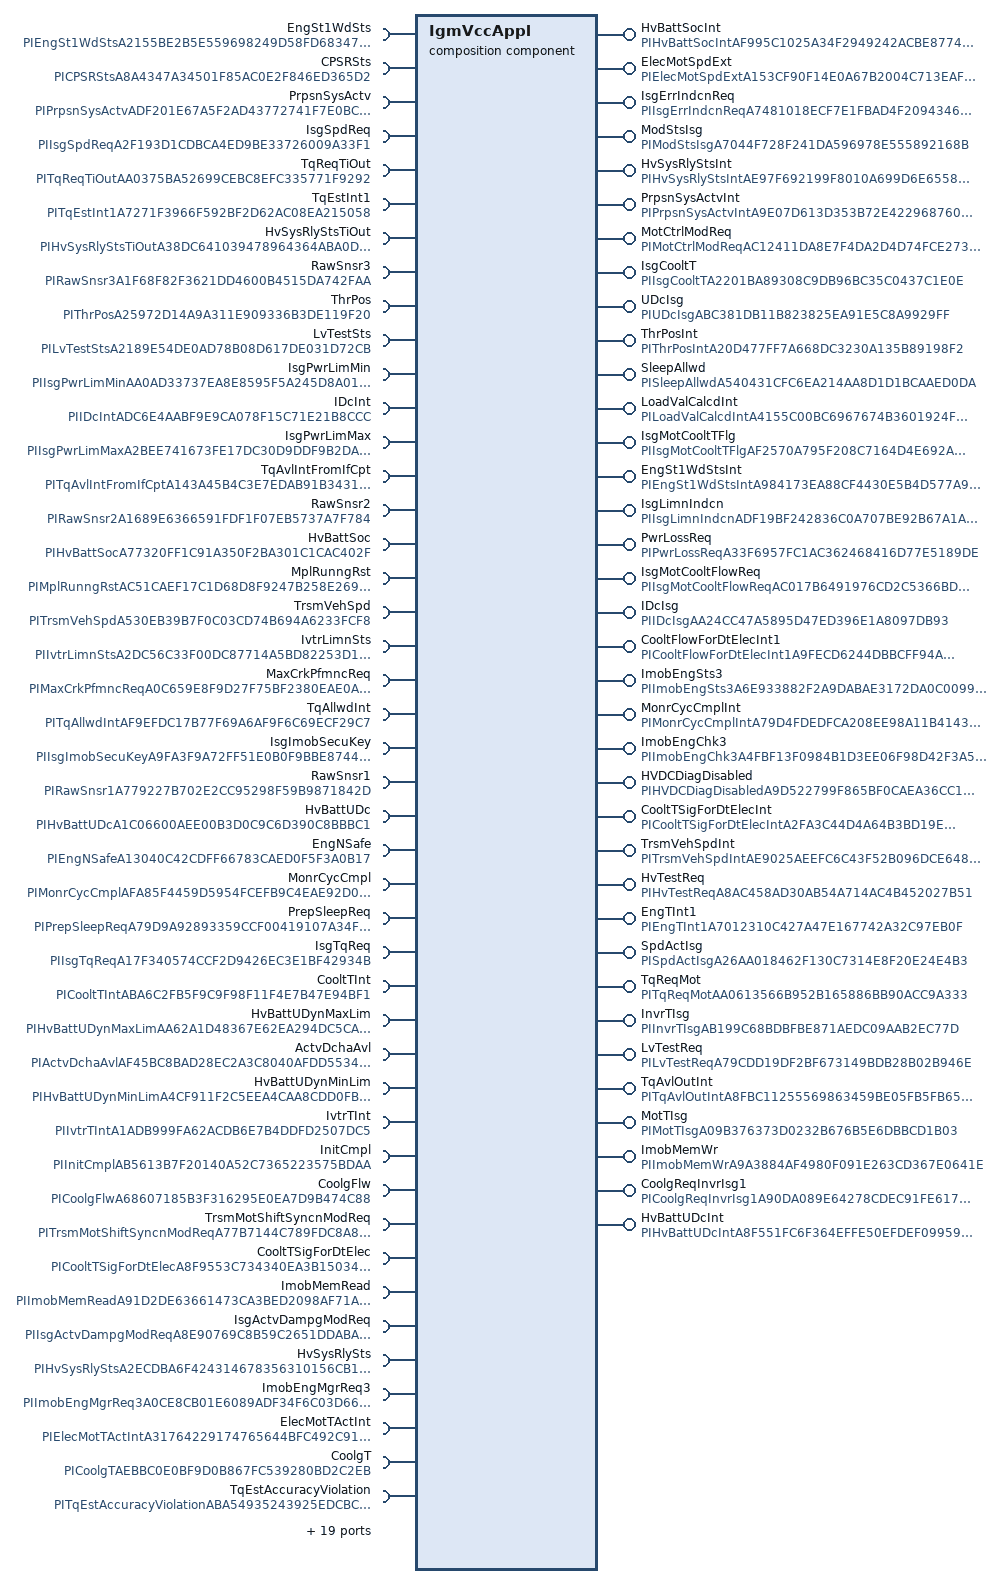
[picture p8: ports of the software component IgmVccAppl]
  composition sw component type IgmVccAppl
    require port EngSt1WdSts: nonqueued-receiver-com-spec{data-element=EngSt1WdSts, init-value=constant-reference=A636F88E591B4F4A2849AD5E95838F02}, required-interface=PIEngSt1WdStsA2155BE2B5E559698249D58FD6834766
    provide port HvBattSocInt: nonqueued-sender-com-spec{data-element=HvBattSocInt, init-value=constant-reference=A566A6590FA167C633F64C4171ADCCB7}, provided-interface=PIHvBattSocIntAF995C1025A34F2949242ACBE8774947
    provide port ElecMotSpdExt: nonqueued-sender-com-spec{data-element=ElecMotSpdExt, init-value=constant-reference=A566A6590FA167C633F64C4171ADCCB7}, provided-interface=PIElecMotSpdExtA153CF90F14E0A67B2004C713EAF537C
    4 x require port:
      CPSRSts: nonqueued-receiver-com-spec{data-element=CPSRSts, init-value=constant-reference=A2AB2663EDCB674997EFCB4941EAE573}, required-interface=PICPSRStsA8A4347A34501F85AC0E2F846ED365D2
      PrpsnSysActv: nonqueued-receiver-com-spec{data-element=PrpsnSysActv, init-value=constant-reference=A2AB2663EDCB674997EFCB4941EAE573}, required-interface=PIPrpsnSysActvADF201E67A5F2AD43772741F7E0BC64C
      IsgSpdReq: nonqueued-receiver-com-spec{data-element=IsgSpdReq, init-value=constant-reference=A566A6590FA167C633F64C4171ADCCB7}, required-interface=PIIsgSpdReqA2F193D1CDBCA4ED9BE33726009A33F1
      TqReqTiOut: nonqueued-receiver-com-spec{data-element=TqReqTiOut, init-value=constant-reference=A2AB2663EDCB674997EFCB4941EAE573}, required-interface=PITqReqTiOutAA0375BA52699CEBC8EFC335771F9292
    provide port IsgErrIndcnReq: nonqueued-sender-com-spec{data-element=IsgErrIndcnReq, init-value=constant-reference=A2AB2663EDCB674997EFCB4941EAE573}, provided-interface=PIIsgErrIndcnReqA7481018ECF7E1FBAD4F2094346D0B08
    require port TqEstInt1: nonqueued-receiver-com-spec{data-element=TqEstInt1, init-value=constant-reference=A566A6590FA167C633F64C4171ADCCB7}, required-interface=PITqEstInt1A7271F3966F592BF2D62AC08EA215058
    provide port ModStsIsg: nonqueued-sender-com-spec{data-element=ModStsIsg, init-value=constant-reference=A2AB2663EDCB674997EFCB4941EAE573}, provided-interface=PIModStsIsgA7044F728F241DA596978E555892168B
    require port HvSysRlyStsTiOut: nonqueued-receiver-com-spec{data-element=HvSysRlyStsTiOut, init-value=constant-reference=A2AB2663EDCB674997EFCB4941EAE573}, required-interface=PIHvSysRlyStsTiOutA38DC641039478964364ABA0D9653B7F
    require port RawSnsr3: nonqueued-receiver-com-spec{data-element=RawSnsr3, init-value=constant-reference=A566A6590FA167C633F64C4171ADCCB7}, required-interface=PIRawSnsr3A1F68F82F3621DD4600B4515DA742FAA
    provide port HvSysRlyStsInt: nonqueued-sender-com-spec{data-element=HvSysRlyStsInt, init-value=constant-reference=A2AB2663EDCB674997EFCB4941EAE573}, provided-interface=PIHvSysRlyStsIntAE97F692199F8010A699D6E6558D46BB
    require port ThrPos: nonqueued-receiver-com-spec{data-element=ThrPos, init-value=constant-reference=A566A6590FA167C633F64C4171ADCCB7}, required-interface=PIThrPosA25972D14A9A311E909336B3DE119F20
    require port LvTestSts: nonqueued-receiver-com-spec{data-element=LvTestSts, init-value=constant-reference=A2AB2663EDCB674997EFCB4941EAE573}, required-interface=PILvTestStsA2189E54DE0AD78B08D617DE031D72CB
    provide port PrpsnSysActvInt: nonqueued-sender-com-spec{data-element=PrpsnSysActvInt, init-value=constant-reference=AD30053758475D867C29EE0F5723584A}, provided-interface=PIPrpsnSysActvIntA9E07D613D353B72E4229687608CB35B
    require port IsgPwrLimMin: nonqueued-receiver-com-spec{data-element=IsgPwrLimMin, init-value=constant-reference=A566A6590FA167C633F64C4171ADCCB7}, required-interface=PIIsgPwrLimMinAA0AD33737EA8E8595F5A245D8A01AAE
    provide port MotCtrlModReq: nonqueued-sender-com-spec{data-element=MotCtrlModReq, init-value=constant-reference=A2AB2663EDCB674997EFCB4941EAE573}, provided-interface=PIMotCtrlModReqAC12411DA8E7F4DA2D4D74FCE273A6CD
    require port IDcInt: nonqueued-receiver-com-spec{data-element=IDcInt, init-value=constant-reference=A566A6590FA167C633F64C4171ADCCB7}, required-interface=PIIDcIntADC6E4AABF9E9CA078F15C71E21B8CCC
    provide port IsgCooltT: nonqueued-sender-com-spec{data-element=IsgCooltT, init-value=constant-reference=A566A6590FA167C633F64C4171ADCCB7}, provided-interface=PIIsgCooltTA2201BA89308C9DB96BC35C0437C1E0E
    provide port UDcIsg: nonqueued-sender-com-spec{data-element=UDcIsg, init-value=constant-reference=A566A6590FA167C633F64C4171ADCCB7}, provided-interface=PIUDcIsgABC381DB11B823825EA91E5C8A9929FF
    4 x require port:
      IsgPwrLimMax: nonqueued-receiver-com-spec{data-element=IsgPwrLimMax, init-value=constant-reference=A566A6590FA167C633F64C4171ADCCB7}, required-interface=PIIsgPwrLimMaxA2BEE741673FE17DC30D9DDF9B2DA05E
      TqAvlIntFromIfCpt: nonqueued-receiver-com-spec{data-element=TqAvlIntFromIfCpt, init-value=constant-reference=A8CFFE3621C1DA13E6FF691AE3A9D3C1}, required-interface=PITqAvlIntFromIfCptA143A45B4C3E7EDAB91B3431BED4F1CC
      RawSnsr2: nonqueued-receiver-com-spec{data-element=RawSnsr2, init-value=constant-reference=A566A6590FA167C633F64C4171ADCCB7}, required-interface=PIRawSnsr2A1689E6366591FDF1F07EB5737A7F784
      HvBattSoc: nonqueued-receiver-com-spec{data-element=HvBattSoc, init-value=constant-reference=A566A6590FA167C633F64C4171ADCCB7}, required-interface=PIHvBattSocA77320FF1C91A350F2BA301C1CAC402F
    provide port ThrPosInt: nonqueued-sender-com-spec{data-element=ThrPosInt, init-value=constant-reference=A566A6590FA167C633F64C4171ADCCB7}, provided-interface=PIThrPosIntA20D477FF7A668DC3230A135B89198F2
    require port MplRunngRst: nonqueued-receiver-com-spec{data-element=MplRunngRst, init-value=constant-reference=A2AB2663EDCB674997EFCB4941EAE573}, required-interface=PIMplRunngRstAC51CAEF17C1D68D8F9247B258E26918
    require port TrsmVehSpd: nonqueued-receiver-com-spec{data-element=TrsmVehSpd, init-value=constant-reference=A566A6590FA167C633F64C4171ADCCB7}, required-interface=PITrsmVehSpdA530EB39B7F0C03CD74B694A6233FCF8
    provide port SleepAllwd: nonqueued-sender-com-spec{data-element=SleepAllwd, init-value=constant-reference=A2AB2663EDCB674997EFCB4941EAE573}, provided-interface=PISleepAllwdA540431CFC6EA214AA8D1D1BCAAED0DA
    require port IvtrLimnSts: nonqueued-receiver-com-spec{data-element=IvtrLimnSts, init-value=constant-reference=A2AB2663EDCB674997EFCB4941EAE573}, required-interface=PIIvtrLimnStsA2DC56C33F00DC87714A5BD82253D1CF
    require port MaxCrkPfmncReq: nonqueued-receiver-com-spec{data-element=MaxCrkPfmncReq, init-value=constant-reference=A2AB2663EDCB674997EFCB4941EAE573}, required-interface=PIMaxCrkPfmncReqA0C659E8F9D27F75BF2380EAE0AA9F4B
    require port TqAllwdInt: nonqueued-receiver-com-spec{data-element=TqAllwdInt, init-value=constant-reference=A5E6433C0EBBF7A278234C60E9932635}, required-interface=PITqAllwdIntAF9EFDC17B77F69A6AF9F6C69ECF29C7
    4 x provide port:
      LoadValCalcdInt: nonqueued-sender-com-spec{data-element=LoadValCalcdInt, init-value=constant-reference=A566A6590FA167C633F64C4171ADCCB7}, provided-interface=PILoadValCalcdIntA4155C00BC6967674B3601924F63EF93
      IsgMotCooltTFlg: nonqueued-sender-com-spec{data-element=IsgMotCooltTFlg, init-value=constant-reference=A2AB2663EDCB674997EFCB4941EAE573}, provided-interface=PIIsgMotCooltTFlgAF2570A795F208C7164D4E692AD44EF5
      EngSt1WdStsInt: nonqueued-sender-com-spec{data-element=EngSt1WdStsInt, init-value=constant-reference=A636F88E591B4F4A2849AD5E95838F02}, provided-interface=PIEngSt1WdStsIntA984173EA88CF4430E5B4D577A9BEE8A
      IsgLimnIndcn: nonqueued-sender-com-spec{data-element=IsgLimnIndcn, init-value=constant-reference=A2AB2663EDCB674997EFCB4941EAE573}, provided-interface=PIIsgLimnIndcnADF19BF242836C0A707BE92B67A1A3C9
    4 x require port:
      IsgImobSecuKey: nonqueued-receiver-com-spec{data-element=IsgImobSecuKey, init-value=constant-reference=AA9EE529BC7CE8EA3A0A158775B5EB0F}, required-interface=PIIsgImobSecuKeyA9FA3F9A72FF51E0B0F9BBE874419BC9
      RawSnsr1: nonqueued-receiver-com-spec{data-element=RawSnsr1, init-value=constant-reference=A566A6590FA167C633F64C4171ADCCB7}, required-interface=PIRawSnsr1A779227B702E2CC95298F59B9871842D
      HvBattUDc: nonqueued-receiver-com-spec{data-element=HvBattUDc, init-value=constant-reference=A566A6590FA167C633F64C4171ADCCB7}, required-interface=PIHvBattUDcA1C06600AEE00B3D0C9C6D390C8BBBC1
      EngNSafe: nonqueued-receiver-com-spec{data-element=EngNSafe, init-value=constant-reference=A1AD216C2FE294940F0F0050DE621F46}, required-interface=PIEngNSafeA13040C42CDFF66783CAED0F5F3A0B17
    provide port PwrLossReq: nonqueued-sender-com-spec{data-element=PwrLossReq, init-value=constant-reference=A566A6590FA167C633F64C4171ADCCB7}, provided-interface=PIPwrLossReqA33F6957FC1AC362468416D77E5189DE
    require port MonrCycCmpl: nonqueued-receiver-com-spec{data-element=MonrCycCmpl, init-value=constant-reference=AD30053758475D867C29EE0F5723584A}, required-interface=PIMonrCycCmplAFA85F4459D5954FCEFB9C4EAE92D0A0
    require port PrepSleepReq: nonqueued-receiver-com-spec{data-element=PrepSleepReq, init-value=constant-reference=A2AB2663EDCB674997EFCB4941EAE573}, required-interface=PIPrepSleepReqA79D9A92893359CCF00419107A34F584
    require port IsgTqReq: nonqueued-receiver-com-spec{data-element=IsgTqReq, init-value=constant-reference=A566A6590FA167C633F64C4171ADCCB7}, required-interface=PIIsgTqReqA17F340574CCF2D9426EC3E1BF42934B
    provide port IsgMotCooltFlowReq: nonqueued-sender-com-spec{data-element=IsgMotCooltFlowReq, init-value=constant-reference=A566A6590FA167C633F64C4171ADCCB7}, provided-interface=PIIsgMotCooltFlowReqAC017B6491976CD2C5366BD7CAC36C21
    require port CooltTInt: nonqueued-receiver-com-spec{data-element=CooltTInt, init-value=constant-reference=A566A6590FA167C633F64C4171ADCCB7}, required-interface=PICooltTIntABA6C2FB5F9C9F98F11F4E7B47E94BF1
    provide port IDcIsg: nonqueued-sender-com-spec{data-element=IDcIsg, init-value=constant-reference=A566A6590FA167C633F64C4171ADCCB7}, provided-interface=PIIDcIsgAA24CC47A5895D47ED396E1A8097DB93
    provide port CooltFlowForDtElecInt1: nonqueued-sender-com-spec{data-element=CooltFlowForDtElecInt1, init-value=constant-reference=A566A6590FA167C633F64C4171ADCCB7}, provided-interface=PICooltFlowForDtElecInt1A9FECD6244DBBCFF94A4D3481557ACF8
    require port HvBattUDynMaxLim: nonqueued-receiver-com-spec{data-element=HvBattUDynMaxLim, init-value=constant-reference=A566A6590FA167C633F64C4171ADCCB7}, required-interface=PIHvBattUDynMaxLimAA62A1D48367E62EA294DC5CAB54933C
    provide port ImobEngSts3: nonqueued-sender-com-spec{data-element=ImobEngSts3, init-value=constant-reference=A2AB2663EDCB674997EFCB4941EAE573}, provided-interface=PIImobEngSts3A6E933882F2A9DABAE3172DA0C0099F9
    require port ActvDchaAvl: nonqueued-receiver-com-spec{data-element=ActvDchaAvl, init-value=constant-reference=A2AB2663EDCB674997EFCB4941EAE573}, required-interface=PIActvDchaAvlAF45BC8BAD28EC2A3C8040AFDD55349F
    provide port MonrCycCmplInt: nonqueued-sender-com-spec{data-element=MonrCycCmplInt, init-value=constant-reference=AD30053758475D867C29EE0F5723584A}, provided-interface=PIMonrCycCmplIntA79D4FDEDFCA208EE98A11B4143D332E
    provide port ImobEngChk3: nonqueued-sender-com-spec{data-element=ImobEngChk3, init-value=constant-reference=A978A77034898F3865BDF257EAEB987B}, provided-interface=PIImobEngChk3A4FBF13F0984B1D3EE06F98D42F3A586
    7 x require port:
      HvBattUDynMinLim: nonqueued-receiver-com-spec{data-element=HvBattUDynMinLim, init-value=constant-reference=A566A6590FA167C633F64C4171ADCCB7}, required-interface=PIHvBattUDynMinLimA4CF911F2C5EEA4CAA8CDD0FB3E6AE92
      IvtrTInt: nonqueued-receiver-com-spec{data-element=IvtrTInt, init-value=constant-reference=A566A6590FA167C633F64C4171ADCCB7}, required-interface=PIIvtrTIntA1ADB999FA62ACDB6E7B4DDFD2507DC5
      InitCmpl: nonqueued-receiver-com-spec{data-element=InitCmpl, init-value=constant-reference=A2AB2663EDCB674997EFCB4941EAE573}, required-interface=PIInitCmplAB5613B7F20140A52C7365223575BDAA
      CoolgFlw: nonqueued-receiver-com-spec{data-element=CoolgFlw, init-value=constant-reference=A566A6590FA167C633F64C4171ADCCB7}, required-interface=PICoolgFlwA68607185B3F316295E0EA7D9B474C88
      TrsmMotShiftSyncnModReq: nonqueued-receiver-com-spec{data-element=TrsmMotShiftSyncnModReq, init-value=constant-reference=A2AB2663EDCB674997EFCB4941EAE573}, required-interface=PITrsmMotShiftSyncnModReqA77B7144C789FDC8A8DF5097F76BCE02
      CooltTSigForDtElec: nonqueued-receiver-com-spec{data-element=CooltTSigForDtElec, init-value=constant-reference=A566A6590FA167C633F64C4171ADCCB7}, required-interface=PICooltTSigForDtElecA8F9553C734340EA3B15034831232D8D
      ImobMemRead: nonqueued-receiver-com-spec{data-element=ImobMemRead, init-value=constant-reference=A2AB2663EDCB674997EFCB4941EAE573}, required-interface=PIImobMemReadA91D2DE63661473CA3BED2098AF71AA2
    provide port HVDCDiagDisabled: nonqueued-sender-com-spec{data-element=HVDCDiagDisabled, init-value=constant-reference=AD30053758475D867C29EE0F5723584A}, provided-interface=PIHVDCDiagDisabledA9D522799F865BF0CAEA36CC194489F7
    provide port CooltTSigForDtElecInt: nonqueued-sender-com-spec{data-element=CooltTSigForDtElecInt, init-value=constant-reference=A566A6590FA167C633F64C4171ADCCB7}, provided-interface=PICooltTSigForDtElecIntA2FA3C44D4A64B3BD19E1FAA3F5036C0
    require port IsgActvDampgModReq: nonqueued-receiver-com-spec{data-element=IsgActvDampgModReq, init-value=constant-reference=A2AB2663EDCB674997EFCB4941EAE573}, required-interface=PIIsgActvDampgModReqA8E90769C8B59C2651DDABA1191E244E
    require port HvSysRlySts: nonqueued-receiver-com-spec{data-element=HvSysRlySts, init-value=constant-reference=A2AB2663EDCB674997EFCB4941EAE573}, required-interface=PIHvSysRlyStsA2ECDBA6F424314678356310156CB116
    require port ImobEngMgrReq3: nonqueued-receiver-com-spec{data-element=ImobEngMgrReq3, init-value=constant-reference=A2DE60DBB38156AAEB7CD85B81802804}, required-interface=PIImobEngMgrReq3A0CE8CB01E6089ADF34F6C03D6663521
    provide port TrsmVehSpdInt: nonqueued-sender-com-spec{data-element=TrsmVehSpdInt, init-value=constant-reference=A566A6590FA167C633F64C4171ADCCB7}, provided-interface=PITrsmVehSpdIntAE9025AEEFC6C43F52B096DCE648E8B2
    7 x require port:
      ElecMotTActInt: nonqueued-receiver-com-spec{data-element=ElecMotTActInt, init-value=constant-reference=A566A6590FA167C633F64C4171ADCCB7}, required-interface=PIElecMotTActIntA31764229174765644BFC492C91799B4
      CoolgT: nonqueued-receiver-com-spec{data-element=CoolgT, init-value=constant-reference=A2AB2663EDCB674997EFCB4941EAE573}, required-interface=PICoolgTAEBBC0E0BF9D0B867FC539280BD2C2EB
      TqEstAccuracyViolation: nonqueued-receiver-com-spec{data-element=TqEstAccuracyViolation, init-value=constant-reference=A2AB2663EDCB674997EFCB4941EAE573}, required-interface=PITqEstAccuracyViolationABA54935243925EDCBC2DC8B5C54F204
      ImobLastSts: nonqueued-receiver-com-spec{data-element=ImobLastSts, init-value=constant-reference=A2AB2663EDCB674997EFCB4941EAE573}, required-interface=PIImobLastStsA8887E0FF05A13A82EF1D5B8DF73E036
      TqEstAccuracyFailed: nonqueued-receiver-com-spec{data-element=TqEstAccuracyFailed, init-value=constant-reference=A2AB2663EDCB674997EFCB4941EAE573}, required-interface=PITqEstAccuracyFailedA4F2A595E6B812A8ABFB998FFD3DDAAF
      TrsmMotShiftSpdSyncnReq: nonqueued-receiver-com-spec{data-element=TrsmMotShiftSpdSyncnReq, init-value=constant-reference=A566A6590FA167C633F64C4171ADCCB7}, required-interface=PITrsmMotShiftSpdSyncnReqAF50800ED4E965216A820B6F93CDEA6B
      CalReq: nonqueued-receiver-com-spec{data-element=CalReq, init-value=constant-reference=A2AB2663EDCB674997EFCB4941EAE573}, required-interface=PICalReqAB866D96E991BDFE56BBA8080ABDEE2B
    provide port HvTestReq: nonqueued-sender-com-spec{data-element=HvTestReq, init-value=constant-reference=A2AB2663EDCB674997EFCB4941EAE573}, provided-interface=PIHvTestReqA8AC458AD30AB54A714AC4B452027B51
    require port EngT: nonqueued-receiver-com-spec{data-element=EngT, init-value=constant-reference=AD7F32376661EA365B8999AB28B9293D}, required-interface=PIEngTA369F8DA2C656E15DF95953DC5DF5F55
    provide port EngTInt1: nonqueued-sender-com-spec{data-element=EngTInt1, init-value=constant-reference=AD7F32376661EA365B8999AB28B9293D}, provided-interface=PIEngTInt1A7012310C427A47E167742A32C97EB0F
    require port LoadValCalcd: nonqueued-receiver-com-spec{data-element=LoadValCalcd, init-value=constant-reference=A566A6590FA167C633F64C4171ADCCB7}, required-interface=PILoadValCalcdA71AA47E92305AFFB5226EB64D908D0B
    provide port SpdActIsg: nonqueued-sender-com-spec{data-element=SpdActIsg, init-value=constant-reference=A2AB2663EDCB674997EFCB4941EAE573}, provided-interface=PISpdActIsgA26AA018462F130C7314E8F20E24E4B3
    require port HvTestSts: nonqueued-receiver-com-spec{data-element=HvTestSts, init-value=constant-reference=A2AB2663EDCB674997EFCB4941EAE573}, required-interface=PIHvTestStsA0081D64681C391764F24F920F8A06AB
    require port CrashSts2: nonqueued-receiver-com-spec{data-element=CrashSts2, init-value=constant-reference=AD30053758475D867C29EE0F5723584A}, required-interface=PICrashSts2A01AE2778BB77865FCC5765A417E5EC0
    require port UDcInt2: nonqueued-receiver-com-spec{data-element=UDcInt2, init-value=constant-reference=A566A6590FA167C633F64C4171ADCCB7}, required-interface=PIUDcInt2AD7BAFA8FA1B35AC404F413D01ED9A21
    provide port TqReqMot: nonqueued-sender-com-spec{data-element=TqReqMot, init-value=constant-reference=A566A6590FA167C633F64C4171ADCCB7}, provided-interface=PITqReqMotAA0613566B952B165886BB90ACC9A333
    provide port InvrTIsg: nonqueued-sender-com-spec{data-element=InvrTIsg, init-value=constant-reference=A566A6590FA167C633F64C4171ADCCB7}, provided-interface=PIInvrTIsgAB199C68BDBFBE871AEDC09AAB2EC77D
    require port CooltFlowForDtElec: nonqueued-receiver-com-spec{data-element=CooltFlowForDtElec, init-value=constant-reference=A566A6590FA167C633F64C4171ADCCB7}, required-interface=PICooltFlowForDtElecAE708B662153AB35A8AE5AAB5AB27F45
    require port MotCtrlModSts: nonqueued-receiver-com-spec{data-element=MotCtrlModSts, init-value=constant-reference=A2AB2663EDCB674997EFCB4941EAE573}, required-interface=PIMotCtrlModStsA1697EA7CF5F8F95BE310EB812C577CA
    require port IsgModReq: nonqueued-receiver-com-spec{data-element=IsgModReq, init-value=constant-reference=A2AB2663EDCB674997EFCB4941EAE573}, required-interface=PIIsgModReqA575D1D5BF18E736EB3FDC768E70B1B3
    provide port LvTestReq: nonqueued-sender-com-spec{data-element=LvTestReq, init-value=constant-reference=A2AB2663EDCB674997EFCB4941EAE573}, provided-interface=PILvTestReqA79CDD19DF2BF673149BDB28B02B946E
    require port HvIlckSts: nonqueued-receiver-com-spec{data-element=HvIlckSts, init-value=constant-reference=AD30053758475D867C29EE0F5723584A}, required-interface=PIHvIlckStsA1EFC296397BCC9F3CEBEEDA3BC51166
    provide port TqAvlOutInt: nonqueued-sender-com-spec{data-element=TqAvlOutInt, init-value=constant-reference=A8CFFE3621C1DA13E6FF691AE3A9D3C1}, provided-interface=PITqAvlOutIntA8FBC11255569863459BE05FB5FB6599
    provide port MotTIsg: nonqueued-sender-com-spec{data-element=MotTIsg, init-value=constant-reference=A566A6590FA167C633F64C4171ADCCB7}, provided-interface=PIMotTIsgA09B376373D0232B676B5E6DBBCD1B03
    require port PrpsnFbLimnIndcn: nonqueued-receiver-com-spec{data-element=PrpsnFbLimnIndcn, init-value=constant-reference=A2AB2663EDCB674997EFCB4941EAE573}, required-interface=PIPrpsnFbLimnIndcnA8C29516BF74EB4BE772A04D646D70E9
    require port IvtrErrSts: nonqueued-receiver-com-spec{data-element=IvtrErrSts, init-value=constant-reference=A2AB2663EDCB674997EFCB4941EAE573}, required-interface=PIIvtrErrStsA48548CF9954C363177D6EDCE964A414
    require port EngCooltInhbFlow: nonqueued-receiver-com-spec{data-element=EngCooltInhbFlow, init-value=constant-reference=A2AB2663EDCB674997EFCB4941EAE573}, required-interface=PIEngCooltInhbFlowAB368AD01AA04308CC6A31C4B6A4CDEC
    provide port ImobMemWr: nonqueued-sender-com-spec{data-element=ImobMemWr, init-value=constant-reference=A2AB2663EDCB674997EFCB4941EAE573}, provided-interface=PIImobMemWrA9A3884AF4980F091E263CD367E0641E
    require port DeactvtTestCom: nonqueued-receiver-com-spec{data-element=DeactvtTestCom, init-value=constant-reference=AD30053758475D867C29EE0F5723584A}, required-interface=PIDeactvtTestComA82AAD4A52C680CF62EA318A5104AC68
    provide port CoolgReqInvrIsg1: nonqueued-sender-com-spec{data-element=CoolgReqInvrIsg1, init-value=constant-reference=A2AB2663EDCB674997EFCB4941EAE573}, provided-interface=PICoolgReqInvrIsg1A90DA089E64278CDEC91FE617833644E
    require port IsgEngSpdOfActvDampg: nonqueued-receiver-com-spec{data-element=IsgEngSpdOfActvDampg, init-value=constant-reference=A566A6590FA167C633F64C4171ADCCB7}, required-interface=PIIsgEngSpdOfActvDampgAB63CB64F3204234FE4ABC77BFA3477D
    provide port HvBattUDcInt: nonqueued-sender-com-spec{data-element=HvBattUDcInt, init-value=constant-reference=A566A6590FA167C633F64C4171ADCCB7}, provided-interface=PIHvBattUDcIntA8F551FC6F364EFFE50EFDEF09959371
    require port SpdActInt: nonqueued-receiver-com-spec{data-element=SpdActInt, init-value=constant-reference=A566A6590FA167C633F64C4171ADCCB7}, required-interface=PISpdActIntA6A96BD3DA561BF55CACA28E83811FE5
    22 x component:
      IvtrElecMotTqAvlCalcnMAIN: type=IvtrElecMotTqAvlCalcn
      IvtrAntiSpinMAIN: type=IvtrAntiSpin
      IvtrTqArbMgrFastMAIN: type=IvtrTqArbMgrFast
      IvtrIDcLimnMAIN: type=IvtrIDcLimn
      IvtrTqArbMgrSlowMAIN: type=IvtrTqArbMgrSlow
      IvtrAntiShuffleCtrlMAIN: type=IvtrAntiShuffleCtrl
      IvtrUDcLimnMAIN: type=IvtrUDcLimn
      CMACIDDIfCptOutMAIN: type=CMACIDDIfCptOut
      IvtrActvDchaMgrMAIN: type=IvtrActvDchaMgr
      IvtrElecMotTLimnMAIN: type=IvtrElecMotTLimn
      IvtrCoolgCtrlMAIN: type=IvtrCoolgCtrl
      CMACIDDIfCptInMAIN: type=CMACIDDIfCptIn
      IvtrSpdSetCtrlMAIN: type=IvtrSpdSetCtrl
      IvtrSpdLimnMAIN: type=IvtrSpdLimn
      IvtrUSetCtrlMAIN: type=IvtrUSetCtrl
      IvtrModMgrMAIN: type=IvtrModMgr
      IvtrErrIndcnMAIN: type=IvtrErrIndcn
      IvtrPwrLimnMAIN: type=IvtrPwrLimn
      IvtrStabyCtrlMAIN: type=IvtrStabyCtrl
      IvtrLimnIndcnMAIN: type=IvtrLimnIndcn
      IsgImmoMAIN: type=IsgImmo
      IvtrOnBdDiagcComDiMAIN: type=IvtrOnBdDiagcComDi
    connect IvtrModMgrMAIN.SpdSetCtrlMod -> IvtrSpdSetCtrlMAIN.SpdSetCtrlMod
    connect CMACIDDIfCptInMAIN.CoolgTInt -> IvtrCoolgCtrlMAIN.CoolgTInt
    connect IvtrAntiSpinMAIN.TqReqIntFromAntiSpin -> IvtrTqArbMgrSlowMAIN.TqReqIntFromAntiSpin
    connect IvtrSpdSetCtrlMAIN.TqReqFromSpdSetCtrl -> IvtrTqArbMgrSlowMAIN.TqReqFromSpdSetCtrl
    connect IvtrCoolgCtrlMAIN.IsgMotCooltFlowReqInt -> CMACIDDIfCptOutMAIN.IsgMotCooltFlowReqInt
    connect IsgImmoMAIN.ImobEngTurnOffAllwd3 -> CMACIDDIfCptInMAIN.ImobEngTurnOffAllwd3
    connect IsgImmoMAIN.ImobEngTurnOffAllwd3 -> IvtrModMgrMAIN.ImobEngTurnOffAllwd3
    connect CMACIDDIfCptInMAIN.EngCooltInhbFlowInt -> IvtrCoolgCtrlMAIN.EngCooltInhbFlowInt
    connect CMACIDDIfCptInMAIN.EngSt1WdStsInt -> IvtrModMgrMAIN.EngSt1WdStsInt
    connect CMACIDDIfCptInMAIN.EngSt1WdStsInt -> IvtrElecMotTLimnMAIN.EngSt1WdStsInt
    connect CMACIDDIfCptInMAIN.EngSt1WdStsInt -> IvtrUDcLimnMAIN.EngSt1WdStsInt
    connect IvtrStabyCtrlMAIN.DiActvDampg -> IvtrAntiShuffleCtrlMAIN.DiActvDampg
    connect IvtrStabyCtrlMAIN.DiAntiSpin -> IvtrAntiSpinMAIN.DiAntiSpin
    connect CMACIDDIfCptInMAIN.PrpsnFbLimnIndcnInt -> IvtrLimnIndcnMAIN.PrpsnFbLimnIndcnInt
    connect CMACIDDIfCptInMAIN.TrsmMotShiftSyncnModReqInt -> IvtrModMgrMAIN.TrsmMotShiftSyncnModReqInt
    connect IvtrSpdLimnMAIN.TqAvlIntFromSpdLimn -> IvtrElecMotTqAvlCalcnMAIN.TqAvlIntFromSpdLimn
    connect CMACIDDIfCptInMAIN.ActvDampgModReqInt -> IvtrAntiShuffleCtrlMAIN.ActvDampgModReqInt
    connect CMACIDDIfCptInMAIN.VehMtnStSafeInt -> IvtrAntiShuffleCtrlMAIN.VehMtnStSafeInt
    connect IvtrModMgrMAIN.IDcLimnOnOff -> IvtrIDcLimnMAIN.IDcLimnOnOff
    connect IvtrSpdLimnMAIN.SpdLimnSts -> IvtrElecMotTqAvlCalcnMAIN.SpdLimnSts
    connect IvtrPwrLimnMAIN.PwrDcLimnSts -> IvtrElecMotTqAvlCalcnMAIN.PwrDcLimnSts
    connect IvtrModMgrMAIN.AnitSpinOnOff -> IvtrAntiSpinMAIN.AnitSpinOnOff
    connect CMACIDDIfCptInMAIN.PwrLimInt -> IvtrPwrLimnMAIN.PwrLimInt
    connect IvtrLimnIndcnMAIN.LimnIndcnInt -> CMACIDDIfCptOutMAIN.LimnIndcnInt
    connect IvtrElecMotTqAvlCalcnMAIN.TqAvlPreDmpg -> IvtrTqArbMgrFastMAIN.TqAvlPreDmpg
    connect CMACIDDIfCptInMAIN.CooltTSigForDtElecInt -> IvtrCoolgCtrlMAIN.CooltTSigForDtElecInt
    connect CMACIDDIfCptInMAIN.ElecMotSpdExt -> IvtrUDcLimnMAIN.ElecMotSpdExt
    connect CMACIDDIfCptInMAIN.ElecMotSpdExt -> IvtrSpdSetCtrlMAIN.ElecMotSpdExt
    connect IvtrIDcLimnMAIN.IDcLimnSts -> IvtrElecMotTqAvlCalcnMAIN.IDcLimnSts
    connect CMACIDDIfCptInMAIN.HvBattUDcInt -> IvtrModMgrMAIN.HvBattUDcInt
    connect CMACIDDIfCptInMAIN.CooltFlowForDtElecInt1 -> IvtrCoolgCtrlMAIN.CooltFlowForDtElecInt1
    connect CMACIDDIfCptOutMAIN.ModStsIsg -> IsgImmoMAIN.ModSts
    connect CMACIDDIfCptInMAIN.PtActrReModReqInt -> IvtrStabyCtrlMAIN.PtActrReModReqInt
    connect IvtrElecMotTLimnMAIN.ElecMotTLimnSts -> IvtrElecMotTqAvlCalcnMAIN.ElecMotTLimnSts
    connect CMACIDDIfCptInMAIN.AxleSlipRelActInt -> IvtrAntiSpinMAIN.AxleSlipRelActInt
    connect IvtrModMgrMAIN.SpdLimnOnOff -> IvtrSpdLimnMAIN.SpdLimnOnOff
    connect IvtrUDcLimnMAIN.TqAvlIntFromUDcLimn -> IvtrElecMotTqAvlCalcnMAIN.TqAvlIntFromUDcLimn
    connect CMACIDDIfCptInMAIN.EngSpdOfActvDampgInt -> IvtrAntiShuffleCtrlMAIN.EngSpdOfActvDampgInt
    connect IvtrModMgrMAIN.TqArbMgrCtrl -> IvtrTqArbMgrSlowMAIN.TqArbMgrCtrl
    connect CMACIDDIfCptInMAIN.DeactvtTextComInt -> IvtrOnBdDiagcComDiMAIN.DeactvtTextComInt
    connect CMACIDDIfCptInMAIN.TqReqInt -> IvtrTqArbMgrSlowMAIN.TqReqInt
    connect CMACIDDIfCptInMAIN.TqReqInt -> IvtrAntiSpinMAIN.TqReqInt
    connect CMACIDDIfCptInMAIN.UDcReqInt -> IvtrUSetCtrlMAIN.UDcReqInt
    connect CMACIDDIfCptInMAIN.SpdIdleReqInt -> IvtrSpdSetCtrlMAIN.SpdIdleReqInt
    connect IvtrModMgrMAIN.PwrDcLimnOnOff -> IvtrPwrLimnMAIN.PwrDcLimnOnOff
    connect IvtrActvDchaMgrMAIN.ActvDchaReq -> IvtrModMgrMAIN.ActvDchaReq
    connect CMACIDDIfCptInMAIN.ModReqInt -> IvtrModMgrMAIN.ModReqInt
    connect CMACIDDIfCptInMAIN.HvSysRlyStsInt -> IvtrActvDchaMgrMAIN.HvSysRlyStsInt
    connect CMACIDDIfCptInMAIN.HvSysRlyStsInt -> IvtrUSetCtrlMAIN.HvSysRlyStsInt
    connect CMACIDDIfCptInMAIN.HvSysRlyStsInt -> IvtrModMgrMAIN.HvSysRlyStsInt
    connect IvtrTqArbMgrFastMAIN.TqReqMot -> IvtrUSetCtrlMAIN.TqReqMot
    connect IvtrTqArbMgrFastMAIN.TqReqMot -> IvtrSpdSetCtrlMAIN.TqReqMot
    connect IvtrTqArbMgrFastMAIN.TqReqMot -> IvtrTqArbMgrSlowMAIN.TqReqMot
    connect IvtrStabyCtrlMAIN.TqReqFromStabyCtrl -> IvtrTqArbMgrSlowMAIN.TqReqFromStabyCtrl
    connect CMACIDDIfCptInMAIN.CoolgFlwInt -> IvtrCoolgCtrlMAIN.CoolgFlwInt
    connect IvtrCoolgCtrlMAIN.CoolgReqInt -> CMACIDDIfCptOutMAIN.CoolgReqInt
    connect IvtrModMgrMAIN.ElecMotTLimnOnOff -> IvtrElecMotTLimnMAIN.ElecMotTLimnOnOff
    connect IvtrTqArbMgrSlowMAIN.TqReqFromTqArbMgrSlow -> IvtrPwrLimnMAIN.TqReqFromTqArbMgrSlow
    connect IvtrTqArbMgrSlowMAIN.TqReqFromTqArbMgrSlow -> IvtrTqArbMgrFastMAIN.TqReqFromTqArbMgrSlow
    connect IvtrPwrLimnMAIN.PwrLossTq -> IvtrUDcLimnMAIN.PwrLossTq
    connect IvtrUSetCtrlMAIN.TqReqFromUSetCtrl -> IvtrTqArbMgrSlowMAIN.TqReqFromUSetCtrl
    connect IvtrPwrLimnMAIN.TqAvlIntFromPwrDcLimn -> IvtrElecMotTqAvlCalcnMAIN.TqAvlIntFromPwrDcLimn
    connect IvtrPwrLimnMAIN.TqAvlIntFromPwrMeclLimn -> IvtrElecMotTqAvlCalcnMAIN.TqAvlIntFromPwrMeclLimn
    connect CMACIDDIfCptInMAIN.CrashSts2Int -> IvtrActvDchaMgrMAIN.CrashSts2Int
    connect IvtrModMgrMAIN.ModStsInt -> CMACIDDIfCptOutMAIN.ModStsInt
    connect CMACIDDIfCptInMAIN.MaxCrkPfmncReqInt -> IvtrModMgrMAIN.MaxCrkPfmncReqInt
    connect IvtrIDcLimnMAIN.TqAvlIntFromIDcLimn -> IvtrElecMotTqAvlCalcnMAIN.TqAvlIntFromIDcLimn
    connect CMACIDDIfCptInMAIN.ImobEngTurnOffAllwdInt -> IvtrModMgrMAIN.ImobEngTurnOffAllwdInt
    connect CMACIDDIfCptInMAIN.SpdRotlForWhlsAtAxleReInt -> IvtrAntiSpinMAIN.SpdRotlForWhlsAtAxleReInt
    connect CMACIDDIfCptInMAIN.SpdRotlForWhlsAtAxleReInt -> IvtrAntiShuffleCtrlMAIN.SpdRotlForWhlsAtAxleReInt
    connect CMACIDDIfCptInMAIN.ImobLastStsInt -> IvtrModMgrMAIN.ImobLastStsInt
    connect IvtrElecMotTLimnMAIN.TqAvlIntFromElecMotTLimn -> IvtrElecMotTqAvlCalcnMAIN.TqAvlIntFromElecMotTLimn
    connect IvtrAntiShuffleCtrlMAIN.TqCorrnFromAntiShuffleCtrl -> IvtrTqArbMgrFastMAIN.TqCorrnFromAntiShuffleCtrl
    connect IvtrElecMotTqAvlCalcnMAIN.TqAvlPostDmpg -> IvtrTqArbMgrFastMAIN.TqAvlPostDmpg
    connect IvtrUDcLimnMAIN.UDcLimnSts -> IvtrElecMotTqAvlCalcnMAIN.UDcLimnSts
    connect IvtrPwrLimnMAIN.PwrMeclLimnSts -> IvtrElecMotTqAvlCalcnMAIN.PwrMeclLimnSts
    connect IvtrModMgrMAIN.USetCtrlMod -> IvtrUSetCtrlMAIN.USetCtrlMod
    connect CMACIDDIfCptInMAIN.VehSpdLgtSafeInt -> IvtrAntiSpinMAIN.VehSpdLgtSafeInt
    connect CMACIDDIfCptInMAIN.HvBattUDynLimInt -> IvtrUDcLimnMAIN.HvBattUDynLimInt
    connect IvtrModMgrMAIN.StabyCtrlOnOff -> IvtrStabyCtrlMAIN.StabyCtrlOnOff
    connect IvtrCoolgCtrlMAIN.IsgMotCooltTFlgInt -> CMACIDDIfCptOutMAIN.IsgMotCooltTFlgInt
    connect IvtrModMgrMAIN.UDcLimnOnOff -> IvtrUDcLimnMAIN.UDcLimnOnOff
    connect CMACIDDIfCptInMAIN.PtTqAtAxleReMinReqInt -> IvtrStabyCtrlMAIN.PtTqAtAxleReMinReqInt
    delegate IvtrCoolgCtrlMAIN.IvtrTInt <-> outer port IgmVccAppl/IvtrTInt
    delegate IvtrCoolgCtrlMAIN.ElecMotTActInt <-> outer port IgmVccAppl/ElecMotTActInt
    delegate IvtrTqArbMgrSlowMAIN.SpdActInt <-> outer port IgmVccAppl/SpdActInt
    delegate IvtrTqArbMgrSlowMAIN.TqReqTiOut <-> outer port IgmVccAppl/TqReqTiOut
    delegate IvtrTqArbMgrSlowMAIN.TqAllwdInt <-> outer port IgmVccAppl/TqAllwdInt
    delegate IvtrModMgrMAIN.SpdActInt <-> outer port IgmVccAppl/SpdActInt
    delegate IvtrModMgrMAIN.TqEstAccuracyFailed <-> outer port IgmVccAppl/TqEstAccuracyFailed
    delegate IvtrModMgrMAIN.MotCtrlModReq <-> outer port IgmVccAppl/MotCtrlModReq
    delegate IvtrModMgrMAIN.InitCmpl <-> outer port IgmVccAppl/InitCmpl
    delegate IvtrModMgrMAIN.HvIlckSts <-> outer port IgmVccAppl/HvIlckSts
    delegate IvtrModMgrMAIN.PrepSleepReq <-> outer port IgmVccAppl/PrepSleepReq
    delegate IvtrModMgrMAIN.SleepAllwd <-> outer port IgmVccAppl/SleepAllwd
    delegate IvtrModMgrMAIN.MplRunngRst <-> outer port IgmVccAppl/MplRunngRst
    delegate IvtrModMgrMAIN.LvTestReq <-> outer port IgmVccAppl/LvTestReq
    delegate IvtrModMgrMAIN.LvTestSts <-> outer port IgmVccAppl/LvTestSts
    delegate IvtrModMgrMAIN.CalReq <-> outer port IgmVccAppl/CalReq
    delegate IvtrModMgrMAIN.IvtrErrSts <-> outer port IgmVccAppl/IvtrErrSts
    delegate IvtrModMgrMAIN.TqEstInt1 <-> outer port IgmVccAppl/TqEstInt1
    delegate IvtrModMgrMAIN.MotCtrlModSts <-> outer port IgmVccAppl/MotCtrlModSts
    delegate IvtrModMgrMAIN.TqAllwdInt <-> outer port IgmVccAppl/TqAllwdInt
    delegate IvtrModMgrMAIN.CPSRSts <-> outer port IgmVccAppl/CPSRSts
    delegate IvtrModMgrMAIN.TqEstAccuracyViolation <-> outer port IgmVccAppl/TqEstAccuracyViolation
    delegate IvtrModMgrMAIN.HvTestReq <-> outer port IgmVccAppl/HvTestReq
    delegate IvtrModMgrMAIN.HVDCDiagDisabled <-> outer port IgmVccAppl/HVDCDiagDisabled
    delegate IvtrModMgrMAIN.HvTestSts <-> outer port IgmVccAppl/HvTestSts
    delegate IvtrTqArbMgrFastMAIN.TqReqMot <-> outer port IgmVccAppl/TqReqMot
    delegate CMACIDDIfCptInMAIN.EngNSafe <-> outer port IgmVccAppl/EngNSafe
    delegate CMACIDDIfCptInMAIN.MaxCrkPfmncReq <-> outer port IgmVccAppl/MaxCrkPfmncReq
    delegate CMACIDDIfCptInMAIN.HvBattUDynMaxLim <-> outer port IgmVccAppl/HvBattUDynMaxLim
    delegate CMACIDDIfCptInMAIN.IsgPwrLimMax <-> outer port IgmVccAppl/IsgPwrLimMax
    delegate CMACIDDIfCptInMAIN.CooltFlowForDtElecInt1 <-> outer port IgmVccAppl/CooltFlowForDtElecInt1
    delegate CMACIDDIfCptInMAIN.CrashSts2 <-> outer port IgmVccAppl/CrashSts2
    delegate CMACIDDIfCptInMAIN.ImobLastSts <-> outer port IgmVccAppl/ImobLastSts
    delegate CMACIDDIfCptInMAIN.HvBattUDcInt <-> outer port IgmVccAppl/HvBattUDcInt
    delegate CMACIDDIfCptInMAIN.CooltFlowForDtElec <-> outer port IgmVccAppl/CooltFlowForDtElec
    delegate CMACIDDIfCptInMAIN.PrpsnFbLimnIndcn <-> outer port IgmVccAppl/PrpsnFbLimnIndcn
    delegate CMACIDDIfCptInMAIN.LoadValCalcdInt <-> outer port IgmVccAppl/LoadValCalcdInt
    delegate CMACIDDIfCptInMAIN.ThrPosInt <-> outer port IgmVccAppl/ThrPosInt
    delegate CMACIDDIfCptInMAIN.TrsmVehSpd <-> outer port IgmVccAppl/TrsmVehSpd
    delegate CMACIDDIfCptInMAIN.EngTInt1 <-> outer port IgmVccAppl/EngTInt1
    delegate CMACIDDIfCptInMAIN.TrsmMotShiftSpdSyncnReq <-> outer port IgmVccAppl/TrsmMotShiftSpdSyncnReq
    delegate CMACIDDIfCptInMAIN.CooltTSigForDtElecInt <-> outer port IgmVccAppl/CooltTSigForDtElecInt
    delegate CMACIDDIfCptInMAIN.IsgPwrLimMin <-> outer port IgmVccAppl/IsgPwrLimMin
    delegate CMACIDDIfCptInMAIN.HvBattUDc <-> outer port IgmVccAppl/HvBattUDc
    delegate CMACIDDIfCptInMAIN.CooltTSigForDtElec <-> outer port IgmVccAppl/CooltTSigForDtElec
    delegate CMACIDDIfCptInMAIN.CoolgT <-> outer port IgmVccAppl/CoolgT
    delegate CMACIDDIfCptInMAIN.HvSysRlyStsInt <-> outer port IgmVccAppl/HvSysRlyStsInt
    delegate CMACIDDIfCptInMAIN.EngSt1WdSts <-> outer port IgmVccAppl/EngSt1WdSts
    delegate CMACIDDIfCptInMAIN.MonrCycCmplInt <-> outer port IgmVccAppl/MonrCycCmplInt
    delegate CMACIDDIfCptInMAIN.MonrCycCmpl <-> outer port IgmVccAppl/MonrCycCmpl
    delegate CMACIDDIfCptInMAIN.ThrPos <-> outer port IgmVccAppl/ThrPos
    delegate CMACIDDIfCptInMAIN.IsgEngSpdOfActvDampg <-> outer port IgmVccAppl/IsgEngSpdOfActvDampg
    delegate CMACIDDIfCptInMAIN.IsgActvDampgModReq <-> outer port IgmVccAppl/IsgActvDampgModReq
    delegate CMACIDDIfCptInMAIN.ElecMotSpdExt <-> outer port IgmVccAppl/ElecMotSpdExt
    delegate CMACIDDIfCptInMAIN.IsgSpdReq <-> outer port IgmVccAppl/IsgSpdReq
    delegate CMACIDDIfCptInMAIN.HvBattSoc <-> outer port IgmVccAppl/HvBattSoc
    delegate CMACIDDIfCptInMAIN.HvSysRlySts <-> outer port IgmVccAppl/HvSysRlySts
    delegate CMACIDDIfCptInMAIN.DeactvtTestCom <-> outer port IgmVccAppl/DeactvtTestCom
    delegate CMACIDDIfCptInMAIN.EngSt1WdStsInt <-> outer port IgmVccAppl/EngSt1WdStsInt
    delegate CMACIDDIfCptInMAIN.PrpsnSysActvInt <-> outer port IgmVccAppl/PrpsnSysActvInt
    delegate CMACIDDIfCptInMAIN.TrsmMotShiftSyncnModReq <-> outer port IgmVccAppl/TrsmMotShiftSyncnModReq
    delegate CMACIDDIfCptInMAIN.LoadValCalcd <-> outer port IgmVccAppl/LoadValCalcd
    delegate CMACIDDIfCptInMAIN.IsgModReq <-> outer port IgmVccAppl/IsgModReq
    delegate CMACIDDIfCptInMAIN.IsgTqReq <-> outer port IgmVccAppl/IsgTqReq
    delegate CMACIDDIfCptInMAIN.EngT <-> outer port IgmVccAppl/EngT
    delegate CMACIDDIfCptInMAIN.EngCooltInhbFlow <-> outer port IgmVccAppl/EngCooltInhbFlow
    delegate CMACIDDIfCptInMAIN.HvBattUDynMinLim <-> outer port IgmVccAppl/HvBattUDynMinLim
    delegate CMACIDDIfCptInMAIN.HvBattSocInt <-> outer port IgmVccAppl/HvBattSocInt
    delegate CMACIDDIfCptInMAIN.CoolgFlw <-> outer port IgmVccAppl/CoolgFlw
    delegate CMACIDDIfCptInMAIN.PrpsnSysActv <-> outer port IgmVccAppl/PrpsnSysActv
    delegate CMACIDDIfCptInMAIN.TrsmVehSpdInt <-> outer port IgmVccAppl/TrsmVehSpdInt
    delegate IvtrPwrLimnMAIN.PwrLossReq <-> outer port IgmVccAppl/PwrLossReq
    delegate IvtrPwrLimnMAIN.IDcInt <-> outer port IgmVccAppl/IDcInt
    delegate IvtrPwrLimnMAIN.TqEstInt1 <-> outer port IgmVccAppl/TqEstInt1
    delegate IvtrPwrLimnMAIN.UDcInt2 <-> outer port IgmVccAppl/UDcInt2
    delegate IvtrPwrLimnMAIN.SpdActInt <-> outer port IgmVccAppl/SpdActInt
    delegate IvtrAntiShuffleCtrlMAIN.TqEstInt1 <-> outer port IgmVccAppl/TqEstInt1
    delegate IvtrAntiShuffleCtrlMAIN.SpdActInt <-> outer port IgmVccAppl/SpdActInt
    delegate IvtrSpdLimnMAIN.SpdActInt <-> outer port IgmVccAppl/SpdActInt
    delegate IvtrSpdLimnMAIN.TqEstInt1 <-> outer port IgmVccAppl/TqEstInt1
    delegate IvtrActvDchaMgrMAIN.HvSysRlyStsTiOut <-> outer port IgmVccAppl/HvSysRlyStsTiOut
    delegate IvtrActvDchaMgrMAIN.ActvDchaAvl <-> outer port IgmVccAppl/ActvDchaAvl
    delegate IvtrActvDchaMgrMAIN.UDcInt2 <-> outer port IgmVccAppl/UDcInt2
    delegate IvtrUSetCtrlMAIN.UDcInt2 <-> outer port IgmVccAppl/UDcInt2
    delegate IvtrIDcLimnMAIN.IDcInt <-> outer port IgmVccAppl/IDcInt
    delegate IvtrIDcLimnMAIN.TqEstInt1 <-> outer port IgmVccAppl/TqEstInt1
    delegate IvtrIDcLimnMAIN.SpdActInt <-> outer port IgmVccAppl/SpdActInt
    delegate IsgImmoMAIN.ImobMemWr <-> outer port IgmVccAppl/ImobMemWr
    delegate IsgImmoMAIN.RawSnsr3 <-> outer port IgmVccAppl/RawSnsr3
    delegate IsgImmoMAIN.ImobMemRead <-> outer port IgmVccAppl/ImobMemRead
    delegate IsgImmoMAIN.IsgImobSecuKey <-> outer port IgmVccAppl/IsgImobSecuKey
    delegate IsgImmoMAIN.ImobEngSts3 <-> outer port IgmVccAppl/ImobEngSts3
    delegate IsgImmoMAIN.RawSnsr1 <-> outer port IgmVccAppl/RawSnsr1
    delegate IsgImmoMAIN.RawSnsr2 <-> outer port IgmVccAppl/RawSnsr2
    delegate IsgImmoMAIN.ImobEngChk3 <-> outer port IgmVccAppl/ImobEngChk3
    delegate IsgImmoMAIN.EngSt1WdSts <-> outer port IgmVccAppl/EngSt1WdSts
    delegate IsgImmoMAIN.ImobEngMgrReq3 <-> outer port IgmVccAppl/ImobEngMgrReq3
    delegate CMACIDDIfCptOutMAIN.IvtrTInt <-> outer port IgmVccAppl/IvtrTInt
    delegate CMACIDDIfCptOutMAIN.IDcInt <-> outer port IgmVccAppl/IDcInt
    delegate CMACIDDIfCptOutMAIN.UDcInt2 <-> outer port IgmVccAppl/UDcInt2
    delegate CMACIDDIfCptOutMAIN.CooltTInt <-> outer port IgmVccAppl/CooltTInt
    delegate CMACIDDIfCptOutMAIN.IDcIsg <-> outer port IgmVccAppl/IDcIsg
    delegate CMACIDDIfCptOutMAIN.IsgErrIndcnReq <-> outer port IgmVccAppl/IsgErrIndcnReq
    delegate CMACIDDIfCptOutMAIN.ElecMotTActInt <-> outer port IgmVccAppl/ElecMotTActInt
    delegate CMACIDDIfCptOutMAIN.IsgLimnIndcn <-> outer port IgmVccAppl/IsgLimnIndcn
    delegate CMACIDDIfCptOutMAIN.InvrTIsg <-> outer port IgmVccAppl/InvrTIsg
    delegate CMACIDDIfCptOutMAIN.IsgMotCooltFlowReq <-> outer port IgmVccAppl/IsgMotCooltFlowReq
    delegate CMACIDDIfCptOutMAIN.IsgCooltT <-> outer port IgmVccAppl/IsgCooltT
    delegate CMACIDDIfCptOutMAIN.UDcIsg <-> outer port IgmVccAppl/UDcIsg
    delegate CMACIDDIfCptOutMAIN.CoolgReqInvrIsg1 <-> outer port IgmVccAppl/CoolgReqInvrIsg1
    delegate CMACIDDIfCptOutMAIN.SpdActInt <-> outer port IgmVccAppl/SpdActInt
    delegate CMACIDDIfCptOutMAIN.MotTIsg <-> outer port IgmVccAppl/MotTIsg
    delegate CMACIDDIfCptOutMAIN.ModStsIsg <-> outer port IgmVccAppl/ModStsIsg
    delegate CMACIDDIfCptOutMAIN.IsgMotCooltTFlg <-> outer port IgmVccAppl/IsgMotCooltTFlg
    delegate CMACIDDIfCptOutMAIN.SpdActIsg <-> outer port IgmVccAppl/SpdActIsg
    delegate IvtrAntiSpinMAIN.SpdActInt <-> outer port IgmVccAppl/SpdActInt
    delegate IvtrAntiSpinMAIN.TqEstInt1 <-> outer port IgmVccAppl/TqEstInt1
    delegate IvtrElecMotTLimnMAIN.ElecMotTActInt <-> outer port IgmVccAppl/ElecMotTActInt
    delegate IvtrElecMotTLimnMAIN.TqEstInt1 <-> outer port IgmVccAppl/TqEstInt1
    delegate IvtrElecMotTLimnMAIN.SpdActInt <-> outer port IgmVccAppl/SpdActInt
    delegate IvtrUDcLimnMAIN.UDcInt2 <-> outer port IgmVccAppl/UDcInt2
    delegate IvtrUDcLimnMAIN.TqEstInt1 <-> outer port IgmVccAppl/TqEstInt1
    delegate IvtrUDcLimnMAIN.SpdActInt <-> outer port IgmVccAppl/SpdActInt
    delegate IvtrSpdSetCtrlMAIN.SpdActInt <-> outer port IgmVccAppl/SpdActInt
    delegate IvtrElecMotTqAvlCalcnMAIN.TqAvlOutInt <-> outer port IgmVccAppl/TqAvlOutInt
    delegate IvtrElecMotTqAvlCalcnMAIN.TqAvlIntFromIfCpt <-> outer port IgmVccAppl/TqAvlIntFromIfCpt
    delegate IvtrElecMotTqAvlCalcnMAIN.IvtrLimnSts <-> outer port IgmVccAppl/IvtrLimnSts
package /ComponentType/IsgSupplIfCpt/IsgSupplIfCptMAIN
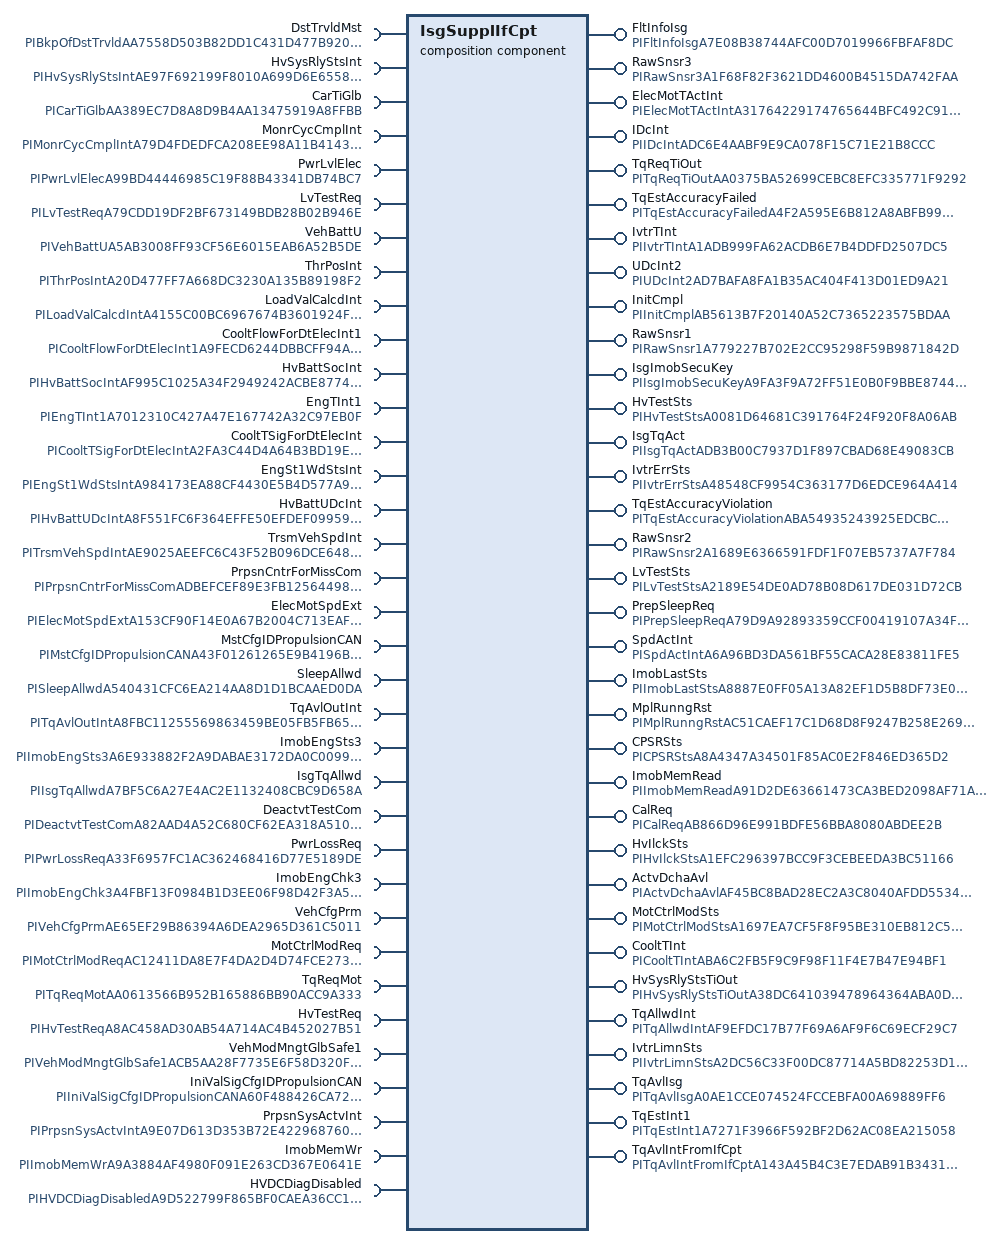
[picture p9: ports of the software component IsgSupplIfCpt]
  composition sw component type IsgSupplIfCpt
    provide port FltInfoIsg: nonqueued-sender-com-spec{data-element=FltInfoIsg, init-value=constant-reference=A2AB2663EDCB674997EFCB4941EAE573}, provided-interface=PIFltInfoIsgA7E08B38744AFC00D7019966FBFAF8DC
    require port DstTrvldMst: nonqueued-receiver-com-spec{data-element=BkpOfDstTrvld, init-value=constant-reference=A566A6590FA167C633F64C4171ADCCB7}, required-interface=PIBkpOfDstTrvldAA7558D503B82DD1C431D477B9209E63
    provide port RawSnsr3: nonqueued-sender-com-spec{data-element=RawSnsr3, init-value=constant-reference=A566A6590FA167C633F64C4171ADCCB7}, provided-interface=PIRawSnsr3A1F68F82F3621DD4600B4515DA742FAA
    require port HvSysRlyStsInt: nonqueued-receiver-com-spec{data-element=HvSysRlyStsInt, init-value=constant-reference=A2AB2663EDCB674997EFCB4941EAE573}, required-interface=PIHvSysRlyStsIntAE97F692199F8010A699D6E6558D46BB
    provide port ElecMotTActInt: nonqueued-sender-com-spec{data-element=ElecMotTActInt, init-value=constant-reference=A566A6590FA167C633F64C4171ADCCB7}, provided-interface=PIElecMotTActIntA31764229174765644BFC492C91799B4
    require port CarTiGlb: nonqueued-receiver-com-spec{data-element=CarTiGlb, init-value=constant-reference=A566A6590FA167C633F64C4171ADCCB7}, required-interface=PICarTiGlbAA389EC7D8A8D9B4AA13475919A8FFBB
    provide port IDcInt: nonqueued-sender-com-spec{data-element=IDcInt, init-value=constant-reference=A566A6590FA167C633F64C4171ADCCB7}, provided-interface=PIIDcIntADC6E4AABF9E9CA078F15C71E21B8CCC
    require port MonrCycCmplInt: nonqueued-receiver-com-spec{data-element=MonrCycCmplInt, init-value=constant-reference=AD30053758475D867C29EE0F5723584A}, required-interface=PIMonrCycCmplIntA79D4FDEDFCA208EE98A11B4143D332E
    provide port TqReqTiOut: nonqueued-sender-com-spec{data-element=TqReqTiOut, init-value=constant-reference=A2AB2663EDCB674997EFCB4941EAE573}, provided-interface=PITqReqTiOutAA0375BA52699CEBC8EFC335771F9292
    require port PwrLvlElec: nonqueued-receiver-com-spec=data-element=PwrLvlElec, required-interface=PIPwrLvlElecA99BD44446985C19F88B43341DB74BC7
    require port LvTestReq: nonqueued-receiver-com-spec{data-element=LvTestReq, init-value=constant-reference=A2AB2663EDCB674997EFCB4941EAE573}, required-interface=PILvTestReqA79CDD19DF2BF673149BDB28B02B946E
    require port VehBattU: nonqueued-receiver-com-spec{data-element=VehBattU, init-value=constant-reference=A57ED80A599FA7B04B45D8F7A2186272}, required-interface=PIVehBattUA5AB3008FF93CF56E6015EAB6A52B5DE
    provide port TqEstAccuracyFailed: nonqueued-sender-com-spec{data-element=TqEstAccuracyFailed, init-value=constant-reference=A2AB2663EDCB674997EFCB4941EAE573}, provided-interface=PITqEstAccuracyFailedA4F2A595E6B812A8ABFB998FFD3DDAAF
    require port ThrPosInt: nonqueued-receiver-com-spec{data-element=ThrPosInt, init-value=constant-reference=A566A6590FA167C633F64C4171ADCCB7}, required-interface=PIThrPosIntA20D477FF7A668DC3230A135B89198F2
    require port LoadValCalcdInt: nonqueued-receiver-com-spec{data-element=LoadValCalcdInt, init-value=constant-reference=A566A6590FA167C633F64C4171ADCCB7}, required-interface=PILoadValCalcdIntA4155C00BC6967674B3601924F63EF93
    provide port IvtrTInt: nonqueued-sender-com-spec{data-element=IvtrTInt, init-value=constant-reference=A566A6590FA167C633F64C4171ADCCB7}, provided-interface=PIIvtrTIntA1ADB999FA62ACDB6E7B4DDFD2507DC5
    provide port UDcInt2: nonqueued-sender-com-spec{data-element=UDcInt2, init-value=constant-reference=A566A6590FA167C633F64C4171ADCCB7}, provided-interface=PIUDcInt2AD7BAFA8FA1B35AC404F413D01ED9A21
    provide port InitCmpl: nonqueued-sender-com-spec{data-element=InitCmpl, init-value=constant-reference=A2AB2663EDCB674997EFCB4941EAE573}, provided-interface=PIInitCmplAB5613B7F20140A52C7365223575BDAA
    require port CooltFlowForDtElecInt1: nonqueued-receiver-com-spec{data-element=CooltFlowForDtElecInt1, init-value=constant-reference=A566A6590FA167C633F64C4171ADCCB7}, required-interface=PICooltFlowForDtElecInt1A9FECD6244DBBCFF94A4D3481557ACF8
    provide port RawSnsr1: nonqueued-sender-com-spec{data-element=RawSnsr1, init-value=constant-reference=A566A6590FA167C633F64C4171ADCCB7}, provided-interface=PIRawSnsr1A779227B702E2CC95298F59B9871842D
    provide port IsgImobSecuKey: nonqueued-sender-com-spec{data-element=IsgImobSecuKey, init-value=constant-reference=ACF2B721822169C938BBC6AFE39038B4}, provided-interface=PIIsgImobSecuKeyA9FA3F9A72FF51E0B0F9BBE874419BC9
    require port HvBattSocInt: nonqueued-receiver-com-spec{data-element=HvBattSocInt, init-value=constant-reference=A61DABA1FBDC405A667816EC215554EE}, required-interface=PIHvBattSocIntAF995C1025A34F2949242ACBE8774947
    require port EngTInt1: nonqueued-receiver-com-spec{data-element=EngTInt1, init-value=constant-reference=AD7F32376661EA365B8999AB28B9293D}, required-interface=PIEngTInt1A7012310C427A47E167742A32C97EB0F
    4 x provide port:
      HvTestSts: nonqueued-sender-com-spec{data-element=HvTestSts, init-value=constant-reference=A2AB2663EDCB674997EFCB4941EAE573}, provided-interface=PIHvTestStsA0081D64681C391764F24F920F8A06AB
      IsgTqAct: nonqueued-sender-com-spec{data-element=IsgTqAct, uses-end-to-end-protection=true, init-value=constant-reference=AF379A41000B10CC950AE01255929993}, provided-interface=PIIsgTqActADB3B00C7937D1F897CBAD68E49083CB
      IvtrErrSts: nonqueued-sender-com-spec{data-element=IvtrErrSts, init-value=constant-reference=A2AB2663EDCB674997EFCB4941EAE573}, provided-interface=PIIvtrErrStsA48548CF9954C363177D6EDCE964A414
      TqEstAccuracyViolation: nonqueued-sender-com-spec{data-element=TqEstAccuracyViolation, init-value=constant-reference=A2AB2663EDCB674997EFCB4941EAE573}, provided-interface=PITqEstAccuracyViolationABA54935243925EDCBC2DC8B5C54F204
    require port CooltTSigForDtElecInt: nonqueued-receiver-com-spec{data-element=CooltTSigForDtElecInt, init-value=constant-reference=A566A6590FA167C633F64C4171ADCCB7}, required-interface=PICooltTSigForDtElecIntA2FA3C44D4A64B3BD19E1FAA3F5036C0
    provide port RawSnsr2: nonqueued-sender-com-spec{data-element=RawSnsr2, init-value=constant-reference=A566A6590FA167C633F64C4171ADCCB7}, provided-interface=PIRawSnsr2A1689E6366591FDF1F07EB5737A7F784
    require port EngSt1WdStsInt: nonqueued-receiver-com-spec{data-element=EngSt1WdStsInt, init-value=constant-reference=A636F88E591B4F4A2849AD5E95838F02}, required-interface=PIEngSt1WdStsIntA984173EA88CF4430E5B4D577A9BEE8A
    require port HvBattUDcInt: nonqueued-receiver-com-spec{data-element=HvBattUDcInt, init-value=constant-reference=A2353A48319CC311B10A39C1A8CCC3AA}, required-interface=PIHvBattUDcIntA8F551FC6F364EFFE50EFDEF09959371
    provide port LvTestSts: nonqueued-sender-com-spec{data-element=LvTestSts, init-value=constant-reference=A2AB2663EDCB674997EFCB4941EAE573}, provided-interface=PILvTestStsA2189E54DE0AD78B08D617DE031D72CB
    require port TrsmVehSpdInt: nonqueued-receiver-com-spec{data-element=TrsmVehSpdInt, init-value=constant-reference=A566A6590FA167C633F64C4171ADCCB7}, required-interface=PITrsmVehSpdIntAE9025AEEFC6C43F52B096DCE648E8B2
    require port PrpsnCntrForMissCom: nonqueued-receiver-com-spec{data-element=PrpsnCntrForMissCom, init-value=constant-reference=A2AB2663EDCB674997EFCB4941EAE573}, required-interface=PIPrpsnCntrForMissComADBEFCEF89E3FB12564498BFE6B58D9A
    provide port PrepSleepReq: nonqueued-sender-com-spec{data-element=PrepSleepReq, init-value=constant-reference=A2AB2663EDCB674997EFCB4941EAE573}, provided-interface=PIPrepSleepReqA79D9A92893359CCF00419107A34F584
    require port ElecMotSpdExt: nonqueued-receiver-com-spec{data-element=ElecMotSpdExt, init-value=constant-reference=A566A6590FA167C633F64C4171ADCCB7}, required-interface=PIElecMotSpdExtA153CF90F14E0A67B2004C713EAF537C
    require port MstCfgIDPropulsionCAN: nonqueued-receiver-com-spec{data-element=MstCfgIDPropulsionCAN, enable-update=true, init-value=constant-reference=A2AB2663EDCB674997EFCB4941EAE573}, required-interface=PIMstCfgIDPropulsionCANA43F01261265E9B4196B2461CF6DBAD8
    require port SleepAllwd: nonqueued-receiver-com-spec{data-element=SleepAllwd, init-value=constant-reference=A2AB2663EDCB674997EFCB4941EAE573}, required-interface=PISleepAllwdA540431CFC6EA214AA8D1D1BCAAED0DA
    provide port SpdActInt: nonqueued-sender-com-spec{data-element=SpdActInt, init-value=constant-reference=A566A6590FA167C633F64C4171ADCCB7}, provided-interface=PISpdActIntA6A96BD3DA561BF55CACA28E83811FE5
    provide port ImobLastSts: nonqueued-sender-com-spec{data-element=ImobLastSts, init-value=constant-reference=A2AB2663EDCB674997EFCB4941EAE573}, provided-interface=PIImobLastStsA8887E0FF05A13A82EF1D5B8DF73E036
    require port TqAvlOutInt: nonqueued-receiver-com-spec{data-element=TqAvlOutInt, init-value=constant-reference=A24B0BD917EA440C0F346C489758B0D2}, required-interface=PITqAvlOutIntA8FBC11255569863459BE05FB5FB6599
    require port ImobEngSts3: nonqueued-receiver-com-spec{data-element=ImobEngSts3, init-value=constant-reference=A2AB2663EDCB674997EFCB4941EAE573}, required-interface=PIImobEngSts3A6E933882F2A9DABAE3172DA0C0099F9
    provide port MplRunngRst: nonqueued-sender-com-spec{data-element=MplRunngRst, init-value=constant-reference=A2AB2663EDCB674997EFCB4941EAE573}, provided-interface=PIMplRunngRstAC51CAEF17C1D68D8F9247B258E26918
    require port IsgTqAllwd: nonqueued-receiver-com-spec{data-element=IsgTqAllwd, init-value=constant-reference=A98E5C9C409339ACD044027A1055A07E}, required-interface=PIIsgTqAllwdA7BF5C6A27E4AC2E1132408CBC9D658A
    provide port CPSRSts: nonqueued-sender-com-spec{data-element=CPSRSts, init-value=constant-reference=A2AB2663EDCB674997EFCB4941EAE573}, provided-interface=PICPSRStsA8A4347A34501F85AC0E2F846ED365D2
    require port DeactvtTestCom: nonqueued-receiver-com-spec{data-element=DeactvtTestCom, init-value=constant-reference=AD30053758475D867C29EE0F5723584A}, required-interface=PIDeactvtTestComA82AAD4A52C680CF62EA318A5104AC68
    provide port ImobMemRead: nonqueued-sender-com-spec{data-element=ImobMemRead, init-value=constant-reference=A2AB2663EDCB674997EFCB4941EAE573}, provided-interface=PIImobMemReadA91D2DE63661473CA3BED2098AF71AA2
    require port PwrLossReq: nonqueued-receiver-com-spec{data-element=PwrLossReq, init-value=constant-reference=A566A6590FA167C633F64C4171ADCCB7}, required-interface=PIPwrLossReqA33F6957FC1AC362468416D77E5189DE
    provide port CalReq: nonqueued-sender-com-spec{data-element=CalReq, init-value=constant-reference=A2AB2663EDCB674997EFCB4941EAE573}, provided-interface=PICalReqAB866D96E991BDFE56BBA8080ABDEE2B
    provide port HvIlckSts: nonqueued-sender-com-spec{data-element=HvIlckSts, init-value=constant-reference=AD30053758475D867C29EE0F5723584A}, provided-interface=PIHvIlckStsA1EFC296397BCC9F3CEBEEDA3BC51166
    require port ImobEngChk3: nonqueued-receiver-com-spec{data-element=ImobEngChk3, init-value=constant-reference=ADB0659449328ECFB4D14A1C7B2086CD}, required-interface=PIImobEngChk3A4FBF13F0984B1D3EE06F98D42F3A586
    provide port ActvDchaAvl: nonqueued-sender-com-spec{data-element=ActvDchaAvl, init-value=constant-reference=AD30053758475D867C29EE0F5723584A}, provided-interface=PIActvDchaAvlAF45BC8BAD28EC2A3C8040AFDD55349F
    require port VehCfgPrm: nonqueued-receiver-com-spec{data-element=VehCfgPrm, init-value=constant-reference=A6B6B7AFC37B54D73A25C7304F41930B}, required-interface=PIVehCfgPrmAE65EF29B86394A6DEA2965D361C5011
    require port MotCtrlModReq: nonqueued-receiver-com-spec{data-element=MotCtrlModReq, init-value=constant-reference=A2AB2663EDCB674997EFCB4941EAE573}, required-interface=PIMotCtrlModReqAC12411DA8E7F4DA2D4D74FCE273A6CD
    require port TqReqMot: nonqueued-receiver-com-spec{data-element=TqReqMot, init-value=constant-reference=A566A6590FA167C633F64C4171ADCCB7}, required-interface=PITqReqMotAA0613566B952B165886BB90ACC9A333
    provide port MotCtrlModSts: nonqueued-sender-com-spec{data-element=MotCtrlModSts, init-value=constant-reference=A2AB2663EDCB674997EFCB4941EAE573}, provided-interface=PIMotCtrlModStsA1697EA7CF5F8F95BE310EB812C577CA
    require port HvTestReq: nonqueued-receiver-com-spec{data-element=HvTestReq, init-value=constant-reference=A2AB2663EDCB674997EFCB4941EAE573}, required-interface=PIHvTestReqA8AC458AD30AB54A714AC4B452027B51
    require port VehModMngtGlbSafe1: nonqueued-receiver-com-spec{data-element=VehModMngtGlbSafe1, init-value=constant-reference=ACF963A02DED26B3921E3180925CE8A3}, required-interface=PIVehModMngtGlbSafe1ACB5AA28F7735E6F58D320F1795FA9D2
    provide port CooltTInt: nonqueued-sender-com-spec{data-element=CooltTInt, init-value=constant-reference=A566A6590FA167C633F64C4171ADCCB7}, provided-interface=PICooltTIntABA6C2FB5F9C9F98F11F4E7B47E94BF1
    provide port HvSysRlyStsTiOut: nonqueued-sender-com-spec{data-element=HvSysRlyStsTiOut, init-value=constant-reference=A2AB2663EDCB674997EFCB4941EAE573}, provided-interface=PIHvSysRlyStsTiOutA38DC641039478964364ABA0D9653B7F
    require port IniValSigCfgIDPropulsionCAN: nonqueued-receiver-com-spec=data-element=IniValSigCfgIDPropulsionCAN, required-interface=PIIniValSigCfgIDPropulsionCANA60F488426CA723C7898718C099DD02C
    provide port TqAllwdInt: nonqueued-sender-com-spec{data-element=TqAllwdInt, init-value=constant-reference=A2AB2663EDCB674997EFCB4941EAE573}, provided-interface=PITqAllwdIntAF9EFDC17B77F69A6AF9F6C69ECF29C7
    provide port IvtrLimnSts: nonqueued-sender-com-spec{data-element=IvtrLimnSts, init-value=constant-reference=A2AB2663EDCB674997EFCB4941EAE573}, provided-interface=PIIvtrLimnStsA2DC56C33F00DC87714A5BD82253D1CF
    require port PrpsnSysActvInt: nonqueued-receiver-com-spec{data-element=PrpsnSysActvInt, init-value=constant-reference=AD30053758475D867C29EE0F5723584A}, required-interface=PIPrpsnSysActvIntA9E07D613D353B72E4229687608CB35B
    require port ImobMemWr: nonqueued-receiver-com-spec{data-element=ImobMemWr, init-value=constant-reference=A2AB2663EDCB674997EFCB4941EAE573}, required-interface=PIImobMemWrA9A3884AF4980F091E263CD367E0641E
    require port HVDCDiagDisabled: nonqueued-receiver-com-spec{data-element=HVDCDiagDisabled, init-value=constant-reference=AD30053758475D867C29EE0F5723584A}, required-interface=PIHVDCDiagDisabledA9D522799F865BF0CAEA36CC194489F7
    provide port TqAvlIsg: nonqueued-sender-com-spec{data-element=TqAvlIsg, init-value=constant-reference=A33A01312D59D0946C249E45DA6690C6}, provided-interface=PITqAvlIsgA0AE1CCE074524FCCEBFA00A69889FF6
    provide port TqEstInt1: nonqueued-sender-com-spec{data-element=TqEstInt1, init-value=constant-reference=A566A6590FA167C633F64C4171ADCCB7}, provided-interface=PITqEstInt1A7271F3966F592BF2D62AC08EA215058
    provide port TqAvlIntFromIfCpt: nonqueued-sender-com-spec{data-element=TqAvlIntFromIfCpt, init-value=constant-reference=A6571BE8D08FA8624FE034351C65BBB8}, provided-interface=PITqAvlIntFromIfCptA143A45B4C3E7EDAB91B3431BED4F1CC
package /ComponentType/DcDcSuppl/DcDcSupplMAIN
  composition sw component type DcDcSuppl
    require port DcDcActvdReq: nonqueued-receiver-com-spec{data-element=DcDcActvdReq, init-value=constant-reference=A2AB2663EDCB674997EFCB4941EAE573}, required-interface=PIDcDcActvdReqA302D3884E8C2093F934F0B3D9C4B780
    4 x provide port:
      LimnIndcnDcDc: nonqueued-sender-com-spec{data-element=LimnIndcnDcDc, init-value=constant-reference=A2AB2663EDCB674997EFCB4941EAE573}, provided-interface=PILimnIndcnDcDcAFA63C2417E8A681AB5D0573B3EFF44A
      FltDcDc: nonqueued-sender-com-spec{data-element=FltDcDc, init-value=constant-reference=A2AB2663EDCB674997EFCB4941EAE573}, provided-interface=PIFltDcDcAA68F75B8142F4211A964DCC6C977A50
      IDcDcActLoSide: nonqueued-sender-com-spec{data-element=IDcDcActLoSide, init-value=constant-reference=A2AB2663EDCB674997EFCB4941EAE573}, provided-interface=PIIDcDcActLoSideAB86FC040C6B68F76DC289353488FF07
      DcDcActvd: nonqueued-sender-com-spec{data-element=DcDcActvd, init-value=constant-reference=A2AB2663EDCB674997EFCB4941EAE573}, provided-interface=PIDcDcActvdA2A804C0E411403591D0DA528A4C2EFF
    require port HvBattUDc: nonqueued-receiver-com-spec{data-element=HvBattUDc, init-value=constant-reference=A566A6590FA167C633F64C4171ADCCB7}, required-interface=PIHvBattUDcA1C06600AEE00B3D0C9C6D390C8BBBC1
    provide port DcDcCoolgReq: nonqueued-sender-com-spec{data-element=DcDcCoolgReq, init-value=constant-reference=A2AB2663EDCB674997EFCB4941EAE573}, provided-interface=PIDcDcCoolgReqA025114FAC3219ECDC2C16CD8D7EA254
    require port ChrgnUReq: nonqueued-receiver-com-spec{data-element=ChrgnUReq, init-value=constant-reference=A6F8BF8DB078858B4AABFD332A9D9219}, required-interface=PIChrgnUReqABDC99F9167D30ECF66FA96FF394DC82
    require port HvConvPwrAllwd: nonqueued-receiver-com-spec{data-element=HvConvPwrAllwd, init-value=constant-reference=A32713970D3B0BFBCDB5A6CFD6484D49}, required-interface=PIHvConvPwrAllwdA746C45F553BF198868447F6A309DB37
    require port PrpsnFbLimnIndcn: nonqueued-receiver-com-spec{data-element=PrpsnFbLimnIndcn, init-value=constant-reference=A2AB2663EDCB674997EFCB4941EAE573}, required-interface=PIPrpsnFbLimnIndcnA8C29516BF74EB4BE772A04D646D70E9
    provide port FltElecDcDc: nonqueued-sender-com-spec{data-element=FltElecDcDc, init-value=constant-reference=A2AB2663EDCB674997EFCB4941EAE573}, provided-interface=PIFltElecDcDcAFD84EB0989B0A5D7176A63628E1ED74
    require port PwrDcDcAvl: nonqueued-receiver-com-spec{data-element=PwrDcDcAvl, init-value=constant-reference=A566A6590FA167C633F64C4171ADCCB7}, required-interface=PIPwrDcDcAvlA0330DAA85C31A2692F87A90896697E7
    provide port IDcDcActHiSide: nonqueued-sender-com-spec{data-element=IDcDcActHiSide, init-value=constant-reference=A566A6590FA167C633F64C4171ADCCB7}, provided-interface=PIIDcDcActHiSideACA1BEE452F259EF0E33BB117EFA74DE
    provide port UDcDcActHiSide: nonqueued-sender-com-spec{data-element=UDcDcActHiSide, init-value=constant-reference=A566A6590FA167C633F64C4171ADCCB7}, provided-interface=PIUDcDcActHiSideAF3F8A46A8DDF4C9C21D8B7214BF7841
    require port HvSysRlySts: nonqueued-receiver-com-spec{data-element=HvSysRlySts, init-value=constant-reference=A2AB2663EDCB674997EFCB4941EAE573}, required-interface=PIHvSysRlyStsA2ECDBA6F424314678356310156CB116
    provide port TDcDc: nonqueued-sender-com-spec{data-element=TDcDc, init-value=constant-reference=A566A6590FA167C633F64C4171ADCCB7}, provided-interface=PITDcDcA0D6338BB3C5B7F9C454AE38B2D9ED20
    require port VehModMngtGlbSafe1: nonqueued-receiver-com-spec{data-element=VehModMngtGlbSafe1, init-value=constant-reference=ACF963A02DED26B3921E3180925CE8A3}, required-interface=PIVehModMngtGlbSafe1ACB5AA28F7735E6F58D320F1795FA9D2
    provide port IDcDcAvlMaxLoSide: nonqueued-sender-com-spec{data-element=IDcDcAvlMaxLoSide, init-value=constant-reference=A2AB2663EDCB674997EFCB4941EAE573}, provided-interface=PIIDcDcAvlMaxLoSideABECA9784581B76EA605F26FB2B0C603
package /ComponentType/IGM/IGMCMA
  composition sw component type IGM  # System overview: See attachment System Overview Electric Drive system in 7DCT Environment.
    require port HvBattSoc: nonqueued-receiver-com-spec{data-element=HvBattSoc, init-value=constant-reference=A566A6590FA167C633F64C4171ADCCB7}, required-interface=PIHvBattSocA77320FF1C91A350F2BA301C1CAC402F
    require port IsgPwrLimMin: nonqueued-receiver-com-spec{data-element=IsgPwrLimMin, init-value=constant-reference=A566A6590FA167C633F64C4171ADCCB7}, required-interface=PIIsgPwrLimMinAA0AD33737EA8E8595F5A245D8A01AAE
    require port CoolgT: nonqueued-receiver-com-spec{data-element=CoolgT, init-value=constant-reference=A2AB2663EDCB674997EFCB4941EAE573}, required-interface=PICoolgTAEBBC0E0BF9D0B867FC539280BD2C2EB
    provide port MotTIsg: nonqueued-sender-com-spec{data-element=MotTIsg, init-value=constant-reference=A566A6590FA167C633F64C4171ADCCB7}, provided-interface=PIMotTIsgA09B376373D0232B676B5E6DBBCD1B03
    provide port DcDcCoolgReq: nonqueued-sender-com-spec{data-element=DcDcCoolgReq, init-value=constant-reference=A2AB2663EDCB674997EFCB4941EAE573}, provided-interface=PIDcDcCoolgReqA025114FAC3219ECDC2C16CD8D7EA254
    require port VehModMngtGlbSafe1: nonqueued-receiver-com-spec{data-element=VehModMngtGlbSafe1, init-value=constant-reference=ACF963A02DED26B3921E3180925CE8A3}, required-interface=PIVehModMngtGlbSafe1ACB5AA28F7735E6F58D320F1795FA9D2
    require port ChrgnUReq: nonqueued-receiver-com-spec{data-element=ChrgnUReq, init-value=constant-reference=A6F8BF8DB078858B4AABFD332A9D9219}, required-interface=PIChrgnUReqABDC99F9167D30ECF66FA96FF394DC82
    provide port CoolgReqInvrIsg1: nonqueued-sender-com-spec{data-element=CoolgReqInvrIsg1, init-value=constant-reference=A2AB2663EDCB674997EFCB4941EAE573}, provided-interface=PICoolgReqInvrIsg1A90DA089E64278CDEC91FE617833644E
    provide port IDcDcActLoSide: nonqueued-sender-com-spec{data-element=IDcDcActLoSide, init-value=constant-reference=A2AB2663EDCB674997EFCB4941EAE573}, provided-interface=PIIDcDcActLoSideAB86FC040C6B68F76DC289353488FF07
    4 x require port:
      HvSysRlySts: nonqueued-receiver-com-spec{data-element=HvSysRlySts, init-value=constant-reference=A2AB2663EDCB674997EFCB4941EAE573}, required-interface=PIHvSysRlyStsA2ECDBA6F424314678356310156CB116
      ThrPos: nonqueued-receiver-com-spec{data-element=ThrPos, init-value=constant-reference=A566A6590FA167C633F64C4171ADCCB7}, required-interface=PIThrPosA25972D14A9A311E909336B3DE119F20
      EngSt1WdSts: nonqueued-receiver-com-spec{data-element=EngSt1WdSts, init-value=constant-reference=A636F88E591B4F4A2849AD5E95838F02}, required-interface=PIEngSt1WdStsA2155BE2B5E559698249D58FD6834766
      MaxCrkPfmncReq: nonqueued-receiver-com-spec{data-element=MaxCrkPfmncReq, init-value=constant-reference=A2AB2663EDCB674997EFCB4941EAE573}, required-interface=PIMaxCrkPfmncReqA0C659E8F9D27F75BF2380EAE0AA9F4B
    provide port IsgLimnIndcn: nonqueued-sender-com-spec{data-element=IsgLimnIndcn, init-value=constant-reference=A2AB2663EDCB674997EFCB4941EAE573}, provided-interface=PIIsgLimnIndcnADF19BF242836C0A707BE92B67A1A3C9
    4 x require port:
      CarTiGlb: nonqueued-receiver-com-spec{data-element=CarTiGlb, init-value=constant-reference=A566A6590FA167C633F64C4171ADCCB7}, required-interface=PICarTiGlbAA389EC7D8A8D9B4AA13475919A8FFBB
      DcDcActvdReq: nonqueued-receiver-com-spec{data-element=DcDcActvdReq, init-value=constant-reference=A2AB2663EDCB674997EFCB4941EAE573}, required-interface=PIDcDcActvdReqA302D3884E8C2093F934F0B3D9C4B780
      CooltFlowForDtElec: nonqueued-receiver-com-spec{data-element=CooltFlowForDtElec, init-value=constant-reference=A566A6590FA167C633F64C4171ADCCB7}, required-interface=PICooltFlowForDtElecAE708B662153AB35A8AE5AAB5AB27F45
      IsgTqAllwd: nonqueued-receiver-com-spec{data-element=IsgTqAllwd, init-value=constant-reference=A98E5C9C409339ACD044027A1055A07E}, required-interface=PIIsgTqAllwdA7BF5C6A27E4AC2E1132408CBC9D658A
    provide port IDcDcAvlMaxLoSide: nonqueued-sender-com-spec{data-element=IDcDcAvlMaxLoSide, init-value=constant-reference=A2AB2663EDCB674997EFCB4941EAE573}, provided-interface=PIIDcDcAvlMaxLoSideABECA9784581B76EA605F26FB2B0C603
    require port EngT: nonqueued-receiver-com-spec{data-element=EngT, init-value=constant-reference=AD7F32376661EA365B8999AB28B9293D}, required-interface=PIEngTA369F8DA2C656E15DF95953DC5DF5F55
    provide port IDcDcActHiSide: nonqueued-sender-com-spec{data-element=IDcDcActHiSide, init-value=constant-reference=A566A6590FA167C633F64C4171ADCCB7}, provided-interface=PIIDcDcActHiSideACA1BEE452F259EF0E33BB117EFA74DE
    provide port ModStsIsg: nonqueued-sender-com-spec{data-element=ModStsIsg, init-value=constant-reference=A2AB2663EDCB674997EFCB4941EAE573}, provided-interface=PIModStsIsgA7044F728F241DA596978E555892168B
    require port CoolgFlw: nonqueued-receiver-com-spec{data-element=CoolgFlw, init-value=constant-reference=A566A6590FA167C633F64C4171ADCCB7}, required-interface=PICoolgFlwA68607185B3F316295E0EA7D9B474C88
    require port IsgSpdReq: nonqueued-receiver-com-spec{data-element=IsgSpdReq, init-value=constant-reference=A566A6590FA167C633F64C4171ADCCB7}, required-interface=PIIsgSpdReqA2F193D1CDBCA4ED9BE33726009A33F1
    require port VehCfgPrm: nonqueued-receiver-com-spec{data-element=VehCfgPrm, init-value=constant-reference=A6B6B7AFC37B54D73A25C7304F41930B}, required-interface=PIVehCfgPrmAE65EF29B86394A6DEA2965D361C5011
    provide port FltInfoIsg: nonqueued-sender-com-spec{data-element=FltInfoIsg, init-value=constant-reference=A2AB2663EDCB674997EFCB4941EAE573}, provided-interface=PIFltInfoIsgA7E08B38744AFC00D7019966FBFAF8DC
    require port TrsmMotShiftSpdSyncnReq: nonqueued-receiver-com-spec{data-element=TrsmMotShiftSpdSyncnReq, init-value=constant-reference=A566A6590FA167C633F64C4171ADCCB7}, required-interface=PITrsmMotShiftSpdSyncnReqAF50800ED4E965216A820B6F93CDEA6B
    provide port DcDcActvd: nonqueued-sender-com-spec{data-element=DcDcActvd, init-value=constant-reference=A2AB2663EDCB674997EFCB4941EAE573}, provided-interface=PIDcDcActvdA2A804C0E411403591D0DA528A4C2EFF
    require port HvBattUDynMinLim: nonqueued-receiver-com-spec{data-element=HvBattUDynMinLim, init-value=constant-reference=A566A6590FA167C633F64C4171ADCCB7}, required-interface=PIHvBattUDynMinLimA4CF911F2C5EEA4CAA8CDD0FB3E6AE92
    require port ImobEngMgrReq3: nonqueued-receiver-com-spec{data-element=ImobEngMgrReq3, init-value=constant-reference=A2DE60DBB38156AAEB7CD85B81802804}, required-interface=PIImobEngMgrReq3A0CE8CB01E6089ADF34F6C03D6663521
    provide port IDcIsg: nonqueued-sender-com-spec{data-element=IDcIsg, init-value=constant-reference=A566A6590FA167C633F64C4171ADCCB7}, provided-interface=PIIDcIsgAA24CC47A5895D47ED396E1A8097DB93
    4 x require port:
      MonrCycCmpl: nonqueued-receiver-com-spec{data-element=MonrCycCmpl, init-value=constant-reference=AD30053758475D867C29EE0F5723584A}, required-interface=PIMonrCycCmplAFA85F4459D5954FCEFB9C4EAE92D0A0
      DstTrvldMst: nonqueued-receiver-com-spec{data-element=BkpOfDstTrvld, init-value=constant-reference=A566A6590FA167C633F64C4171ADCCB7}, required-interface=PIBkpOfDstTrvldAA7558D503B82DD1C431D477B9209E63
      MstCfgIDPropulsionCAN: nonqueued-receiver-com-spec{data-element=MstCfgIDPropulsionCAN, enable-update=true, init-value=constant-reference=A2AB2663EDCB674997EFCB4941EAE573}, required-interface=PIMstCfgIDPropulsionCANA43F01261265E9B4196B2461CF6DBAD8
      CooltTSigForDtElec: nonqueued-receiver-com-spec{data-element=CooltTSigForDtElec, init-value=constant-reference=A566A6590FA167C633F64C4171ADCCB7}, required-interface=PICooltTSigForDtElecA8F9553C734340EA3B15034831232D8D
    provide port LimnIndcnDcDc: nonqueued-sender-com-spec{data-element=LimnIndcnDcDc, init-value=constant-reference=A2AB2663EDCB674997EFCB4941EAE573}, provided-interface=PILimnIndcnDcDcAFA63C2417E8A681AB5D0573B3EFF44A
    require port TrsmMotShiftSyncnModReq: nonqueued-receiver-com-spec{data-element=TrsmMotShiftSyncnModReq, init-value=constant-reference=A2AB2663EDCB674997EFCB4941EAE573}, required-interface=PITrsmMotShiftSyncnModReqA77B7144C789FDC8A8DF5097F76BCE02
    require port HvBattUDynMaxLim: nonqueued-receiver-com-spec{data-element=HvBattUDynMaxLim, init-value=constant-reference=A566A6590FA167C633F64C4171ADCCB7}, required-interface=PIHvBattUDynMaxLimAA62A1D48367E62EA294DC5CAB54933C
    provide port UDcIsg: nonqueued-sender-com-spec{data-element=UDcIsg, init-value=constant-reference=A566A6590FA167C633F64C4171ADCCB7}, provided-interface=PIUDcIsgABC381DB11B823825EA91E5C8A9929FF
    require port IsgEngSpdOfActvDampg: nonqueued-receiver-com-spec{data-element=IsgEngSpdOfActvDampg, init-value=constant-reference=A566A6590FA167C633F64C4171ADCCB7}, required-interface=PIIsgEngSpdOfActvDampgAB63CB64F3204234FE4ABC77BFA3477D
    require port IsgModReq: nonqueued-receiver-com-spec{data-element=IsgModReq, init-value=constant-reference=A2AB2663EDCB674997EFCB4941EAE573}, required-interface=PIIsgModReqA575D1D5BF18E736EB3FDC768E70B1B3
    provide port FltElecDcDc: nonqueued-sender-com-spec{data-element=FltElecDcDc, init-value=constant-reference=A2AB2663EDCB674997EFCB4941EAE573}, provided-interface=PIFltElecDcDcAFD84EB0989B0A5D7176A63628E1ED74
    require port PwrDcDcAvl: nonqueued-receiver-com-spec{data-element=PwrDcDcAvl, init-value=constant-reference=A566A6590FA167C633F64C4171ADCCB7}, required-interface=PIPwrDcDcAvlA0330DAA85C31A2692F87A90896697E7
    require port IsgTqReq: nonqueued-receiver-com-spec{data-element=IsgTqReq, init-value=constant-reference=A566A6590FA167C633F64C4171ADCCB7}, required-interface=PIIsgTqReqA17F340574CCF2D9426EC3E1BF42934B
    provide port IsgTqAct: nonqueued-sender-com-spec{data-element=IsgTqAct, uses-end-to-end-protection=true, init-value=constant-reference=AF379A41000B10CC950AE01255929993}, provided-interface=PIIsgTqActADB3B00C7937D1F897CBAD68E49083CB
    require port PrpsnFbLimnIndcn: nonqueued-receiver-com-spec{data-element=PrpsnFbLimnIndcn, init-value=constant-reference=A2AB2663EDCB674997EFCB4941EAE573}, required-interface=PIPrpsnFbLimnIndcnA8C29516BF74EB4BE772A04D646D70E9
    provide port IsgErrIndcnReq: nonqueued-sender-com-spec{data-element=IsgErrIndcnReq, init-value=constant-reference=A2AB2663EDCB674997EFCB4941EAE573}, provided-interface=PIIsgErrIndcnReqA7481018ECF7E1FBAD4F2094346D0B08
    require port EngNSafe: nonqueued-receiver-com-spec{data-element=EngNSafe, init-value=constant-reference=A1AD216C2FE294940F0F0050DE621F46}, required-interface=PIEngNSafeA13040C42CDFF66783CAED0F5F3A0B17
    provide port ImobEngChk3: nonqueued-sender-com-spec{data-element=ImobEngChk3, init-value=constant-reference=A978A77034898F3865BDF257EAEB987B}, provided-interface=PIImobEngChk3A4FBF13F0984B1D3EE06F98D42F3A586
    provide port TDcDc: nonqueued-sender-com-spec{data-element=TDcDc, init-value=constant-reference=A566A6590FA167C633F64C4171ADCCB7}, provided-interface=PITDcDcA0D6338BB3C5B7F9C454AE38B2D9ED20
    provide port TqAvlIsg: nonqueued-sender-com-spec{data-element=TqAvlIsg, init-value=constant-reference=A33A01312D59D0946C249E45DA6690C6}, provided-interface=PITqAvlIsgA0AE1CCE074524FCCEBFA00A69889FF6
    require port PrpsnCntrForMissCom: nonqueued-receiver-com-spec{data-element=PrpsnCntrForMissCom, init-value=constant-reference=A2AB2663EDCB674997EFCB4941EAE573}, required-interface=PIPrpsnCntrForMissComADBEFCEF89E3FB12564498BFE6B58D9A
    provide port IsgMotCooltTFlg: nonqueued-sender-com-spec{data-element=IsgMotCooltTFlg, init-value=constant-reference=A2AB2663EDCB674997EFCB4941EAE573}, provided-interface=PIIsgMotCooltTFlgAF2570A795F208C7164D4E692AD44EF5
    5 x require port:
      EngCooltInhbFlow: nonqueued-receiver-com-spec{data-element=EngCooltInhbFlow, init-value=constant-reference=A2AB2663EDCB674997EFCB4941EAE573}, required-interface=PIEngCooltInhbFlowAB368AD01AA04308CC6A31C4B6A4CDEC
      HvBattUDc: nonqueued-receiver-com-spec{data-element=HvBattUDc, init-value=constant-reference=A566A6590FA167C633F64C4171ADCCB7}, required-interface=PIHvBattUDcA1C06600AEE00B3D0C9C6D390C8BBBC1
      TrsmVehSpd: nonqueued-receiver-com-spec{data-element=TrsmVehSpd, init-value=constant-reference=A566A6590FA167C633F64C4171ADCCB7}, required-interface=PITrsmVehSpdA530EB39B7F0C03CD74B694A6233FCF8
      CrashSts2: nonqueued-receiver-com-spec{data-element=CrashSts2, init-value=constant-reference=AD30053758475D867C29EE0F5723584A}, required-interface=PICrashSts2A01AE2778BB77865FCC5765A417E5EC0
      IsgPwrLimMax: nonqueued-receiver-com-spec{data-element=IsgPwrLimMax, init-value=constant-reference=A566A6590FA167C633F64C4171ADCCB7}, required-interface=PIIsgPwrLimMaxA2BEE741673FE17DC30D9DDF9B2DA05E
    provide port FltDcDc: nonqueued-sender-com-spec{data-element=FltDcDc, init-value=constant-reference=A2AB2663EDCB674997EFCB4941EAE573}, provided-interface=PIFltDcDcAA68F75B8142F4211A964DCC6C977A50
    require port IsgActvDampgModReq: nonqueued-receiver-com-spec{data-element=IsgActvDampgModReq, init-value=constant-reference=A2AB2663EDCB674997EFCB4941EAE573}, required-interface=PIIsgActvDampgModReqA8E90769C8B59C2651DDABA1191E244E
    require port LoadValCalcd: nonqueued-receiver-com-spec{data-element=LoadValCalcd, init-value=constant-reference=A566A6590FA167C633F64C4171ADCCB7}, required-interface=PILoadValCalcdA71AA47E92305AFFB5226EB64D908D0B
    provide port ImobEngSts3: nonqueued-sender-com-spec{data-element=ImobEngSts3, init-value=constant-reference=A2AB2663EDCB674997EFCB4941EAE573}, provided-interface=PIImobEngSts3A6E933882F2A9DABAE3172DA0C0099F9
    require port HvConvPwrAllwd: nonqueued-receiver-com-spec{data-element=HvConvPwrAllwd, init-value=constant-reference=A32713970D3B0BFBCDB5A6CFD6484D49}, required-interface=PIHvConvPwrAllwdA746C45F553BF198868447F6A309DB37
    require port PrpsnSysActv: nonqueued-receiver-com-spec{data-element=PrpsnSysActv, init-value=constant-reference=A2AB2663EDCB674997EFCB4941EAE573}, required-interface=PIPrpsnSysActvADF201E67A5F2AD43772741F7E0BC64C
    provide port IsgCooltT: nonqueued-sender-com-spec{data-element=IsgCooltT, init-value=constant-reference=A566A6590FA167C633F64C4171ADCCB7}, provided-interface=PIIsgCooltTA2201BA89308C9DB96BC35C0437C1E0E
    require port VehBattU: nonqueued-receiver-com-spec{data-element=VehBattU, init-value=constant-reference=A57ED80A599FA7B04B45D8F7A2186272}, required-interface=PIVehBattUA5AB3008FF93CF56E6015EAB6A52B5DE
    provide port InvrTIsg: nonqueued-sender-com-spec{data-element=InvrTIsg, init-value=constant-reference=A566A6590FA167C633F64C4171ADCCB7}, provided-interface=PIInvrTIsgAB199C68BDBFBE871AEDC09AAB2EC77D
    require port PwrLvlElec: nonqueued-receiver-com-spec=data-element=PwrLvlElec, required-interface=PIPwrLvlElecA99BD44446985C19F88B43341DB74BC7
    require port IniValSigCfgIDPropulsionCAN: nonqueued-receiver-com-spec=data-element=IniValSigCfgIDPropulsionCAN, required-interface=PIIniValSigCfgIDPropulsionCANA60F488426CA723C7898718C099DD02C
    provide port SpdActIsg: nonqueued-sender-com-spec{data-element=SpdActIsg, init-value=constant-reference=A2AB2663EDCB674997EFCB4941EAE573}, provided-interface=PISpdActIsgA26AA018462F130C7314E8F20E24E4B3
    require port DeactvtTestCom: nonqueued-receiver-com-spec{data-element=DeactvtTestCom, init-value=constant-reference=AD30053758475D867C29EE0F5723584A}, required-interface=PIDeactvtTestComA82AAD4A52C680CF62EA318A5104AC68
    provide port IsgMotCooltFlowReq: nonqueued-sender-com-spec{data-element=IsgMotCooltFlowReq, init-value=constant-reference=A566A6590FA167C633F64C4171ADCCB7}, provided-interface=PIIsgMotCooltFlowReqAC017B6491976CD2C5366BD7CAC36C21
    provide port UDcDcActHiSide: nonqueued-sender-com-spec{data-element=UDcDcActHiSide, init-value=constant-reference=A566A6590FA167C633F64C4171ADCCB7}, provided-interface=PIUDcDcActHiSideAF3F8A46A8DDF4C9C21D8B7214BF7841
    component IgmVccApplMAIN: type=IgmVccAppl
    component DcDcSupplMAIN: type=DcDcSuppl
    component IsgSupplIfCptMAIN: type=IsgSupplIfCpt
    connect IsgSupplIfCptMAIN.LvTestSts -> IgmVccApplMAIN.LvTestSts
    connect IgmVccApplMAIN.PrpsnSysActvInt -> IsgSupplIfCptMAIN.PrpsnSysActvInt
    connect IsgSupplIfCptMAIN.HvTestSts -> IgmVccApplMAIN.HvTestSts
    connect IsgSupplIfCptMAIN.ElecMotTActInt -> IgmVccApplMAIN.ElecMotTActInt
    connect IsgSupplIfCptMAIN.ImobLastSts -> IgmVccApplMAIN.ImobLastSts
    connect IgmVccApplMAIN.HvTestReq -> IsgSupplIfCptMAIN.HvTestReq
    connect IsgSupplIfCptMAIN.UDcInt2 -> IgmVccApplMAIN.UDcInt2
    connect IgmVccApplMAIN.LoadValCalcdInt -> IsgSupplIfCptMAIN.LoadValCalcdInt
    connect IsgSupplIfCptMAIN.HvIlckSts -> IgmVccApplMAIN.HvIlckSts
    connect IsgSupplIfCptMAIN.TqEstAccuracyFailed -> IgmVccApplMAIN.TqEstAccuracyFailed
    connect IsgSupplIfCptMAIN.HvSysRlyStsTiOut -> IgmVccApplMAIN.HvSysRlyStsTiOut
    connect IsgSupplIfCptMAIN.RawSnsr1 -> IgmVccApplMAIN.RawSnsr1
    connect IsgSupplIfCptMAIN.IvtrLimnSts -> IgmVccApplMAIN.IvtrLimnSts
    connect IgmVccApplMAIN.EngSt1WdStsInt -> IsgSupplIfCptMAIN.EngSt1WdStsInt
    connect IgmVccApplMAIN.ThrPosInt -> IsgSupplIfCptMAIN.ThrPosInt
    connect IgmVccApplMAIN.CooltTSigForDtElecInt -> IsgSupplIfCptMAIN.CooltTSigForDtElecInt
    connect IsgSupplIfCptMAIN.PrepSleepReq -> IgmVccApplMAIN.PrepSleepReq
    connect IgmVccApplMAIN.PwrLossReq -> IsgSupplIfCptMAIN.PwrLossReq
    connect IsgSupplIfCptMAIN.TqEstInt1 -> IgmVccApplMAIN.TqEstInt1
    connect IsgSupplIfCptMAIN.TqAvlIntFromIfCpt -> IgmVccApplMAIN.TqAvlIntFromIfCpt
    connect IgmVccApplMAIN.SleepAllwd -> IsgSupplIfCptMAIN.SleepAllwd
    connect IsgSupplIfCptMAIN.MotCtrlModSts -> IgmVccApplMAIN.MotCtrlModSts
    connect IgmVccApplMAIN.HvBattUDcInt -> IsgSupplIfCptMAIN.HvBattUDcInt
    connect IgmVccApplMAIN.EngTInt1 -> IsgSupplIfCptMAIN.EngTInt1
    connect IgmVccApplMAIN.HvSysRlyStsInt -> IsgSupplIfCptMAIN.HvSysRlyStsInt
    connect IsgSupplIfCptMAIN.TqEstAccuracyViolation -> IgmVccApplMAIN.TqEstAccuracyViolation
    connect IgmVccApplMAIN.MonrCycCmplInt -> IsgSupplIfCptMAIN.MonrCycCmplInt
    connect IgmVccApplMAIN.CooltFlowForDtElecInt1 -> IsgSupplIfCptMAIN.CooltFlowForDtElecInt1
    connect IgmVccApplMAIN.HvBattSocInt -> IsgSupplIfCptMAIN.HvBattSocInt
    connect IgmVccApplMAIN.HVDCDiagDisabled -> IsgSupplIfCptMAIN.HVDCDiagDisabled
    connect IgmVccApplMAIN.ImobEngChk3 -> IsgSupplIfCptMAIN.ImobEngChk3
    connect IsgSupplIfCptMAIN.TqAllwdInt -> IgmVccApplMAIN.TqAllwdInt
    connect IgmVccApplMAIN.ImobMemWr -> IsgSupplIfCptMAIN.ImobMemWr
    connect IgmVccApplMAIN.ImobEngSts3 -> IsgSupplIfCptMAIN.ImobEngSts3
    connect IsgSupplIfCptMAIN.CooltTInt -> IgmVccApplMAIN.CooltTInt
    connect IsgSupplIfCptMAIN.SpdActInt -> IgmVccApplMAIN.SpdActInt
    connect IgmVccApplMAIN.ElecMotSpdExt -> IsgSupplIfCptMAIN.ElecMotSpdExt
    connect IgmVccApplMAIN.TqReqMot -> IsgSupplIfCptMAIN.TqReqMot
    connect IsgSupplIfCptMAIN.InitCmpl -> IgmVccApplMAIN.InitCmpl
    connect IsgSupplIfCptMAIN.IvtrTInt -> IgmVccApplMAIN.IvtrTInt
    connect IsgSupplIfCptMAIN.RawSnsr2 -> IgmVccApplMAIN.RawSnsr2
    connect IsgSupplIfCptMAIN.CPSRSts -> IgmVccApplMAIN.CPSRSts
    connect IgmVccApplMAIN.MotCtrlModReq -> IsgSupplIfCptMAIN.MotCtrlModReq
    connect IsgSupplIfCptMAIN.ImobMemRead -> IgmVccApplMAIN.ImobMemRead
    connect IgmVccApplMAIN.LvTestReq -> IsgSupplIfCptMAIN.LvTestReq
    connect IsgSupplIfCptMAIN.IDcInt -> IgmVccApplMAIN.IDcInt
    connect IsgSupplIfCptMAIN.CalReq -> IgmVccApplMAIN.CalReq
    connect IgmVccApplMAIN.TqAvlOutInt -> IsgSupplIfCptMAIN.TqAvlOutInt
    connect IsgSupplIfCptMAIN.RawSnsr3 -> IgmVccApplMAIN.RawSnsr3
    connect IsgSupplIfCptMAIN.IvtrErrSts -> IgmVccApplMAIN.IvtrErrSts
    connect IsgSupplIfCptMAIN.ActvDchaAvl -> IgmVccApplMAIN.ActvDchaAvl
    connect IsgSupplIfCptMAIN.IsgImobSecuKey -> IgmVccApplMAIN.IsgImobSecuKey
    connect IsgSupplIfCptMAIN.TqReqTiOut -> IgmVccApplMAIN.TqReqTiOut
    connect IgmVccApplMAIN.TrsmVehSpdInt -> IsgSupplIfCptMAIN.TrsmVehSpdInt
    connect IsgSupplIfCptMAIN.MplRunngRst -> IgmVccApplMAIN.MplRunngRst
    delegate IgmVccApplMAIN.EngSt1WdSts <-> outer port IGM/EngSt1WdSts
    delegate IgmVccApplMAIN.PrpsnSysActv <-> outer port IGM/PrpsnSysActv
    delegate IgmVccApplMAIN.IsgSpdReq <-> outer port IGM/IsgSpdReq
    delegate IgmVccApplMAIN.IsgErrIndcnReq <-> outer port IGM/IsgErrIndcnReq
    delegate IgmVccApplMAIN.ModStsIsg <-> outer port IGM/ModStsIsg
    delegate IgmVccApplMAIN.ThrPos <-> outer port IGM/ThrPos
    delegate IgmVccApplMAIN.IsgPwrLimMin <-> outer port IGM/IsgPwrLimMin
    delegate IgmVccApplMAIN.IsgCooltT <-> outer port IGM/IsgCooltT
    delegate IgmVccApplMAIN.UDcIsg <-> outer port IGM/UDcIsg
    delegate IgmVccApplMAIN.IsgPwrLimMax <-> outer port IGM/IsgPwrLimMax
    delegate IgmVccApplMAIN.HvBattSoc <-> outer port IGM/HvBattSoc
    delegate IgmVccApplMAIN.TrsmVehSpd <-> outer port IGM/TrsmVehSpd
    delegate IgmVccApplMAIN.MaxCrkPfmncReq <-> outer port IGM/MaxCrkPfmncReq
    delegate IgmVccApplMAIN.IsgMotCooltTFlg <-> outer port IGM/IsgMotCooltTFlg
    delegate IgmVccApplMAIN.IsgLimnIndcn <-> outer port IGM/IsgLimnIndcn
    delegate IgmVccApplMAIN.HvBattUDc <-> outer port IGM/HvBattUDc
    delegate IgmVccApplMAIN.EngNSafe <-> outer port IGM/EngNSafe
    delegate IgmVccApplMAIN.MonrCycCmpl <-> outer port IGM/MonrCycCmpl
    delegate IgmVccApplMAIN.IsgTqReq <-> outer port IGM/IsgTqReq
    delegate IgmVccApplMAIN.IsgMotCooltFlowReq <-> outer port IGM/IsgMotCooltFlowReq
    delegate IgmVccApplMAIN.IDcIsg <-> outer port IGM/IDcIsg
    delegate IgmVccApplMAIN.HvBattUDynMaxLim <-> outer port IGM/HvBattUDynMaxLim
    delegate IgmVccApplMAIN.ImobEngSts3 <-> outer port IGM/ImobEngSts3
    delegate IgmVccApplMAIN.ImobEngChk3 <-> outer port IGM/ImobEngChk3
    delegate IgmVccApplMAIN.HvBattUDynMinLim <-> outer port IGM/HvBattUDynMinLim
    delegate IgmVccApplMAIN.CoolgFlw <-> outer port IGM/CoolgFlw
    delegate IgmVccApplMAIN.TrsmMotShiftSyncnModReq <-> outer port IGM/TrsmMotShiftSyncnModReq
    delegate IgmVccApplMAIN.CooltTSigForDtElec <-> outer port IGM/CooltTSigForDtElec
    delegate IgmVccApplMAIN.IsgActvDampgModReq <-> outer port IGM/IsgActvDampgModReq
    delegate IgmVccApplMAIN.HvSysRlySts <-> outer port IGM/HvSysRlySts
    delegate IgmVccApplMAIN.ImobEngMgrReq3 <-> outer port IGM/ImobEngMgrReq3
    delegate IgmVccApplMAIN.CoolgT <-> outer port IGM/CoolgT
    delegate IgmVccApplMAIN.TrsmMotShiftSpdSyncnReq <-> outer port IGM/TrsmMotShiftSpdSyncnReq
    delegate IgmVccApplMAIN.EngT <-> outer port IGM/EngT
    delegate IgmVccApplMAIN.LoadValCalcd <-> outer port IGM/LoadValCalcd
    delegate IgmVccApplMAIN.SpdActIsg <-> outer port IGM/SpdActIsg
    delegate IgmVccApplMAIN.CrashSts2 <-> outer port IGM/CrashSts2
    delegate IgmVccApplMAIN.InvrTIsg <-> outer port IGM/InvrTIsg
    delegate IgmVccApplMAIN.CooltFlowForDtElec <-> outer port IGM/CooltFlowForDtElec
    delegate IgmVccApplMAIN.IsgModReq <-> outer port IGM/IsgModReq
    delegate IgmVccApplMAIN.MotTIsg <-> outer port IGM/MotTIsg
    delegate IgmVccApplMAIN.PrpsnFbLimnIndcn <-> outer port IGM/PrpsnFbLimnIndcn
    delegate IgmVccApplMAIN.EngCooltInhbFlow <-> outer port IGM/EngCooltInhbFlow
    delegate IgmVccApplMAIN.DeactvtTestCom <-> outer port IGM/DeactvtTestCom
    delegate IgmVccApplMAIN.CoolgReqInvrIsg1 <-> outer port IGM/CoolgReqInvrIsg1
    delegate IgmVccApplMAIN.IsgEngSpdOfActvDampg <-> outer port IGM/IsgEngSpdOfActvDampg
    delegate IsgSupplIfCptMAIN.FltInfoIsg <-> outer port IGM/FltInfoIsg
    delegate IsgSupplIfCptMAIN.DstTrvldMst <-> outer port IGM/DstTrvldMst
    delegate IsgSupplIfCptMAIN.CarTiGlb <-> outer port IGM/CarTiGlb
    delegate IsgSupplIfCptMAIN.PwrLvlElec <-> outer port IGM/PwrLvlElec
    delegate IsgSupplIfCptMAIN.VehBattU <-> outer port IGM/VehBattU
    delegate IsgSupplIfCptMAIN.IsgTqAct <-> outer port IGM/IsgTqAct
    delegate IsgSupplIfCptMAIN.PrpsnCntrForMissCom <-> outer port IGM/PrpsnCntrForMissCom
    delegate IsgSupplIfCptMAIN.MstCfgIDPropulsionCAN <-> outer port IGM/MstCfgIDPropulsionCAN
    delegate IsgSupplIfCptMAIN.IsgTqAllwd <-> outer port IGM/IsgTqAllwd
    delegate IsgSupplIfCptMAIN.DeactvtTestCom <-> outer port IGM/DeactvtTestCom
    delegate IsgSupplIfCptMAIN.VehCfgPrm <-> outer port IGM/VehCfgPrm
    delegate IsgSupplIfCptMAIN.VehModMngtGlbSafe1 <-> outer port IGM/VehModMngtGlbSafe1
    delegate IsgSupplIfCptMAIN.IniValSigCfgIDPropulsionCAN <-> outer port IGM/IniValSigCfgIDPropulsionCAN
    delegate IsgSupplIfCptMAIN.TqAvlIsg <-> outer port IGM/TqAvlIsg
    delegate DcDcSupplMAIN.DcDcActvdReq <-> outer port IGM/DcDcActvdReq
    delegate DcDcSupplMAIN.LimnIndcnDcDc <-> outer port IGM/LimnIndcnDcDc
    delegate DcDcSupplMAIN.FltDcDc <-> outer port IGM/FltDcDc
    delegate DcDcSupplMAIN.IDcDcActLoSide <-> outer port IGM/IDcDcActLoSide
    delegate DcDcSupplMAIN.DcDcActvd <-> outer port IGM/DcDcActvd
    delegate DcDcSupplMAIN.HvBattUDc <-> outer port IGM/HvBattUDc
    delegate DcDcSupplMAIN.DcDcCoolgReq <-> outer port IGM/DcDcCoolgReq
    delegate DcDcSupplMAIN.ChrgnUReq <-> outer port IGM/ChrgnUReq
    delegate DcDcSupplMAIN.HvConvPwrAllwd <-> outer port IGM/HvConvPwrAllwd
    delegate DcDcSupplMAIN.PrpsnFbLimnIndcn <-> outer port IGM/PrpsnFbLimnIndcn
    delegate DcDcSupplMAIN.FltElecDcDc <-> outer port IGM/FltElecDcDc
    delegate DcDcSupplMAIN.PwrDcDcAvl <-> outer port IGM/PwrDcDcAvl
    delegate DcDcSupplMAIN.IDcDcActHiSide <-> outer port IGM/IDcDcActHiSide
    delegate DcDcSupplMAIN.UDcDcActHiSide <-> outer port IGM/UDcDcActHiSide
    delegate DcDcSupplMAIN.HvSysRlySts <-> outer port IGM/HvSysRlySts
    delegate DcDcSupplMAIN.TDcDc <-> outer port IGM/TDcDc
    delegate DcDcSupplMAIN.VehModMngtGlbSafe1 <-> outer port IGM/VehModMngtGlbSafe1
    delegate DcDcSupplMAIN.IDcDcAvlMaxLoSide <-> outer port IGM/IDcDcAvlMaxLoSide
package /EndToEnd
  end to end protection set MainEndToEndSet
    end to end protection AE40F2706A9A1F61815547BCC9F2C730: end-to-end-profile={category=PROFILE_VCC, data-ids=70, data-id-mode=0, data-length=41, max-delta-counter-init=0, crc-offset=0, counter-offset=8}, end-to-end-protection-variable-prototype
    end to end protection AD1896401C8C67C03ADFFCC4D45CF494: end-to-end-profile={category=PROFILE_VCC, data-ids=70, data-id-mode=0, data-length=41, max-delta-counter-init=0, crc-offset=0, counter-offset=8}, end-to-end-protection-variable-prototype=IsgTqAct.IsgTqAct
package /VehicleProject
  system SYSTEM: category=SYSTEM_EXTRACT, system-version=0.0.23;ECU-SW: IGM / CMA
    root-software-compositions:
      root sw composition prototype IGM: software-composition=IGM
